VERSION ""

NS_ :

BS_:

BU_: VCU GW PTC EVCOM MCU BMS POD ADCU Diag

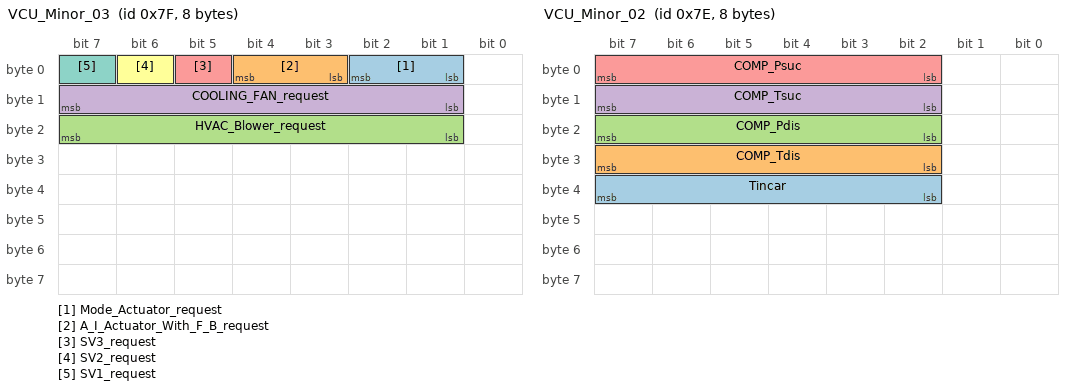
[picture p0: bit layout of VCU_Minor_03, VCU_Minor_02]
BO_ 127 VCU_Minor_03: 8 Vector__XXX
 SG_ Mode_Actuator_request : 2|2@0+ (1,0) [0|2] ""  VCU
 SG_ A_I_Actuator_With_F_B_request : 4|2@0+ (1,0) [0|2] ""  VCU
 SG_ HVAC_Blower_request : 23|7@0+ (1,0) [0|100] "%"  VCU
 SG_ COOLING_FAN_request : 15|7@0+ (1,0) [0|100] "%"  VCU
 SG_ SV3_request : 5|1@0+ (1,0) [0|1] ""  VCU
 SG_ SV2_request : 6|1@0+ (1,0) [0|1] ""  VCU
 SG_ SV1_request : 7|1@0+ (1,0) [0|1] ""  VCU

BO_ 126 VCU_Minor_02: 8 VCU
 SG_ Tincar : 39|6@0+ (0.1,0) [0|5] "V" Vector__XXX
 SG_ COMP_Tdis : 31|6@0+ (0.1,0) [0|5] "V" Vector__XXX
 SG_ COMP_Pdis : 23|6@0+ (0.1,0) [0|5] "V" Vector__XXX
 SG_ COMP_Tsuc : 15|6@0+ (0.1,0) [0|5] "V" Vector__XXX
 SG_ COMP_Psuc : 7|6@0+ (0.1,0) [0|5] "V" Vector__XXX

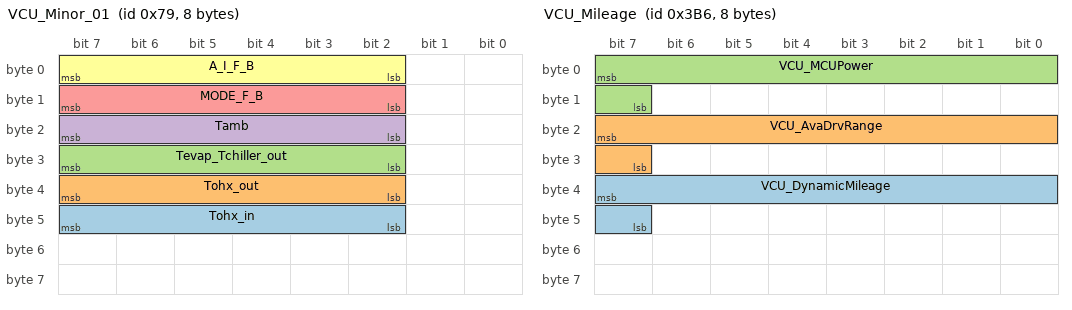
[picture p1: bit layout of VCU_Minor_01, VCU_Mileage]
BO_ 121 VCU_Minor_01: 8 VCU
 SG_ Tohx_in : 47|6@0+ (0.1,0) [0|5] "V" Vector__XXX
 SG_ Tohx_out : 39|6@0+ (0.1,0) [0|5] "V" Vector__XXX
 SG_ Tevap_Tchiller_out : 31|6@0+ (0.1,0) [0|5] "V" Vector__XXX
 SG_ Tamb : 23|6@0+ (0.1,0) [0|5] "V" Vector__XXX
 SG_ MODE_F_B : 15|6@0+ (0.1,0) [0|5] "V" Vector__XXX
 SG_ A_I_F_B : 7|6@0+ (0.1,0) [0|5] "V" Vector__XXX

BO_ 950 VCU_Mileage: 8 Vector__XXX
 SG_ VCU_DynamicMileage : 39|9@0+ (1,0) [0|500] "Km" Vector__XXX
 SG_ VCU_AvaDrvRange : 23|9@0+ (1,0) [0|500] "Km" Vector__XXX
 SG_ VCU_MCUPower : 7|9@0+ (1,-200) [-200|200] "kW" Vector__XXX

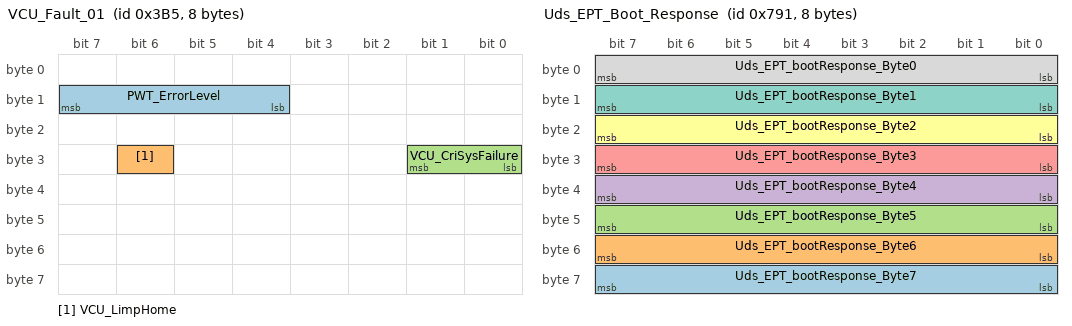
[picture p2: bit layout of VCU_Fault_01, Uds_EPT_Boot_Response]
BO_ 949 VCU_Fault_01: 8 Vector__XXX
 SG_ PWT_ErrorLevel : 15|4@0+ (1,0) [0|15] "" Vector__XXX
 SG_ VCU_LimpHome : 30|1@0+ (1,0) [0|1] "" Vector__XXX
 SG_ VCU_CriSysFailure : 25|2@0+ (1,0) [0|3] "" Vector__XXX

BO_ 1937 Uds_EPT_Boot_Response: 8 Vector__XXX
 SG_ Uds_EPT_bootResponse_Byte7 : 56|8@1+ (1,0) [0|0] ""  Diag
 SG_ Uds_EPT_bootResponse_Byte6 : 48|8@1+ (1,0) [0|0] ""  Diag
 SG_ Uds_EPT_bootResponse_Byte5 : 40|8@1+ (1,0) [0|0] ""  Diag
 SG_ Uds_EPT_bootResponse_Byte4 : 32|8@1+ (1,0) [0|0] ""  Diag
 SG_ Uds_EPT_bootResponse_Byte3 : 24|8@1+ (1,0) [0|0] ""  Diag
 SG_ Uds_EPT_bootResponse_Byte2 : 16|8@1+ (1,0) [0|0] ""  Diag
 SG_ Uds_EPT_bootResponse_Byte1 : 8|8@1+ (1,0) [0|0] ""  Diag
 SG_ Uds_EPT_bootResponse_Byte0 : 0|8@1+ (1,0) [0|0] ""  Diag

BO_ 1809 Uds_EPT_Boot_Request: 8 Diag
 SG_ UDS_EPT_BootCmd3 : 16|8@1+ (1,0) [0|0] "" Vector__XXX
 SG_ UDS_EPT_BootCmd2 : 8|8@1+ (1,0) [0|0] "" Vector__XXX
 SG_ UDS_EPT_BootCmd1 : 0|8@1+ (1,0) [0|0] "" Vector__XXX

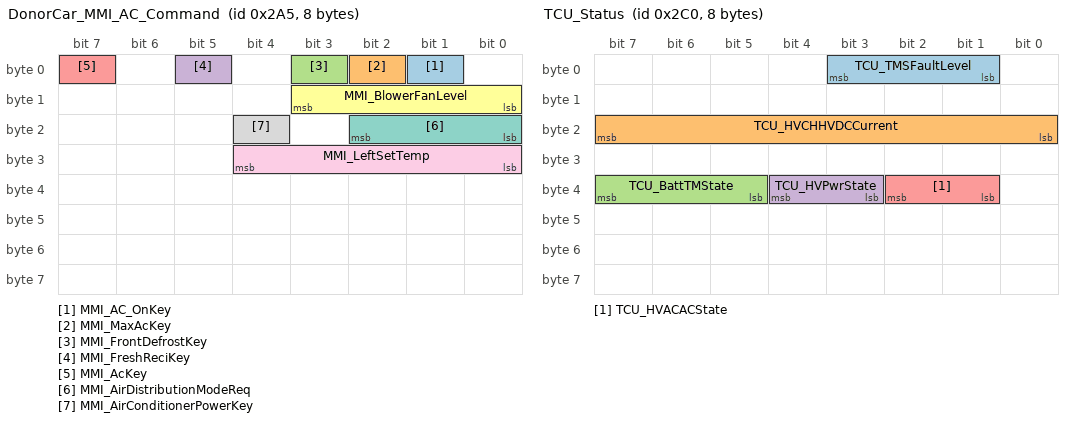
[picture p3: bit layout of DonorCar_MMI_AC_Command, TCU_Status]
BO_ 677 DonorCar_MMI_AC_Command: 8 GW
 SG_ MMI_AC_OnKey : 1|1@0+ (1,0) [0|1] "" Vector__XXX
 SG_ MMI_MaxAcKey : 2|1@0+ (1,0) [0|1] "" Vector__XXX
 SG_ MMI_FrontDefrostKey : 3|1@0+ (1,0) [0|1] "" Vector__XXX
 SG_ MMI_FreshReciKey : 5|1@0+ (1,0) [0|1] "" Vector__XXX
 SG_ MMI_AcKey : 7|1@0+ (1,0) [0|1] "" Vector__XXX
 SG_ MMI_BlowerFanLevel : 11|4@0+ (1,0) [0|15] "" Vector__XXX
 SG_ MMI_AirDistributionModeReq : 18|3@0+ (1,0) [0|7] "" Vector__XXX
 SG_ MMI_AirConditionerPowerKey : 20|1@0+ (1,0) [0|1] "" Vector__XXX
 SG_ MMI_LeftSetTemp : 28|5@0+ (0.5,17) [17|31.5] "℃" Vector__XXX

BO_ 704 TCU_Status: 8 Vector__XXX
 SG_ TCU_TMSFaultLevel : 3|3@0+ (1,0) [0|3] ""  BMS,ADCU
 SG_ TCU_HVCHHVDCCurrent : 23|8@0+ (0.25,0) [0|63.5] "A"  ADCU
 SG_ TCU_BattTMState : 39|3@0+ (1,0) [0|7] ""  BMS
 SG_ TCU_HVPwrState : 36|2@0+ (1,0) [0|3] ""  ADCU
 SG_ TCU_HVACACState : 34|2@0+ (1,0) [0|4] ""  GW

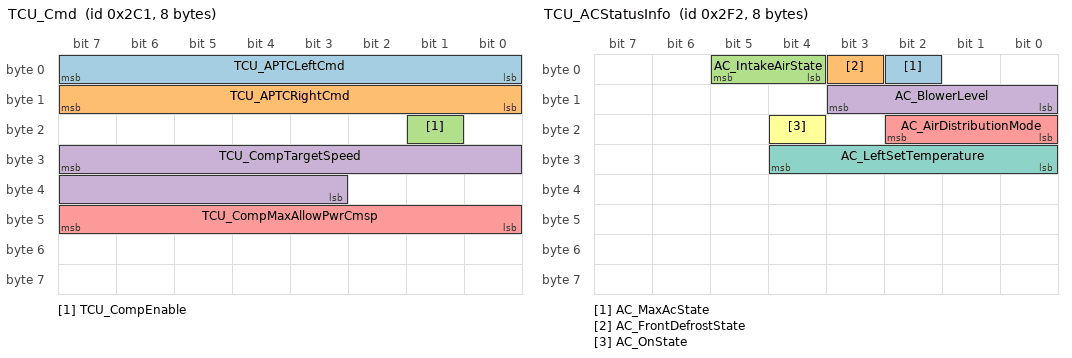
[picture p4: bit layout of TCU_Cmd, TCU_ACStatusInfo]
BO_ 705 TCU_Cmd: 8 Vector__XXX
 SG_ TCU_APTCLeftCmd : 7|8@0+ (1,0) [0|100] "%"  PTC
 SG_ TCU_APTCRightCmd : 15|8@0+ (1,0) [0|100] "%"  PTC
 SG_ TCU_CompEnable : 17|1@0- (1,0) [0|1] ""  EVCOM
 SG_ TCU_CompTargetSpeed : 31|13@0- (1,0) [0|8191] "rpm"  EVCOM
 SG_ TCU_CompMaxAllowPwrCmsp : 47|8@0- (0.04,0) [0|10.16] "KW"  EVCOM

BO_ 706 TCU_AmbientTemp: 8 Vector__XXX
 SG_ TCU_AmbientTemperature : 7|8@0+ (1,-50) [-50|205] ""  GW,ADCU

BO_ 754 TCU_ACStatusInfo: 8 Vector__XXX
 SG_ AC_MaxAcState : 2|1@0+ (1,0) [0|1] ""  GW
 SG_ AC_FrontDefrostState : 3|1@0+ (1,0) [0|1] ""  GW
 SG_ AC_IntakeAirState : 5|2@0+ (1,0) [0|3] ""  GW
 SG_ AC_BlowerLevel : 11|4@0+ (1,0) [0|15] ""  GW
 SG_ AC_AirDistributionMode : 18|3@0+ (1,0) [0|7] ""  GW
 SG_ AC_OnState : 20|1@0+ (1,0) [0|1] ""  GW
 SG_ AC_LeftSetTemperature : 28|5@0+ (0.5,17) [17.5|31.5] "℃"  GW

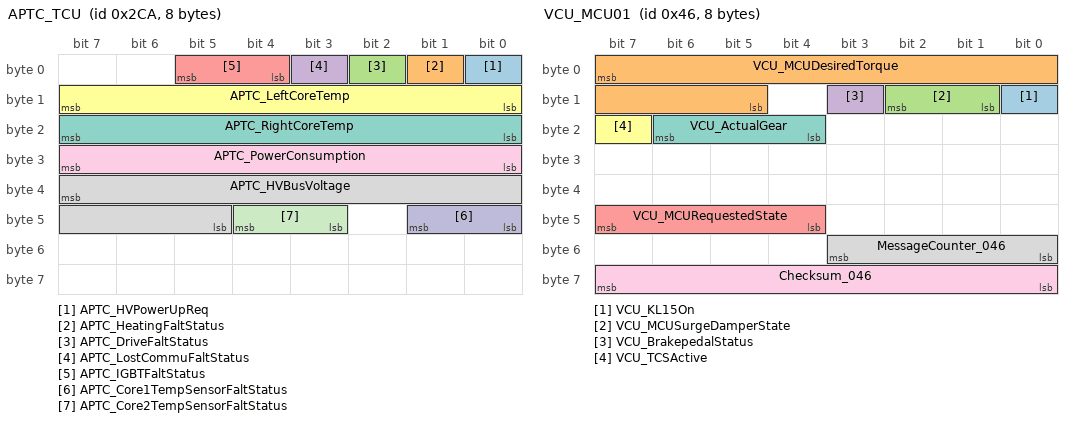
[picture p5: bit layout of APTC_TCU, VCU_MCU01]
BO_ 714 APTC_TCU: 8 PTC
 SG_ APTC_HVPowerUpReq : 0|1@0+ (1,0) [0|1] "" Vector__XXX
 SG_ APTC_HeatingFaltStatus : 1|1@0+ (1,0) [0|1] "" Vector__XXX
 SG_ APTC_DriveFaltStatus : 2|1@0+ (1,0) [0|1] "" Vector__XXX
 SG_ APTC_LostCommuFaltStatus : 3|1@0+ (1,0) [0|1] "" Vector__XXX
 SG_ APTC_IGBTFaltStatus : 5|2@0+ (1,0) [0|3] "" Vector__XXX
 SG_ APTC_LeftCoreTemp : 15|8@0+ (1,-40) [-40|215] "deg" Vector__XXX
 SG_ APTC_RightCoreTemp : 23|8@0+ (1,-40) [-40|215] "deg" Vector__XXX
 SG_ APTC_HVBusVoltage : 39|11@0+ (0.05,0) [0|1020] "V" Vector__XXX
 SG_ APTC_PowerConsumption : 31|8@0+ (0.04,0) [0|10.2] "KW" Vector__XXX
 SG_ APTC_Core1TempSensorFaltStatus : 41|2@0+ (1,0) [0|3] "" Vector__XXX
 SG_ APTC_Core2TempSensorFaltStatus : 44|2@0+ (1,0) [0|3] "" Vector__XXX

BO_ 715 EVCOM_State: 8 EVCOM
 SG_ EVCOM_OverPwrDropFreqError : 0|1@0+ (1,0) [0|1] "" Vector__XXX
 SG_ EVCOM_OverCurDropFreqError : 1|1@0+ (1,0) [0|1] "" Vector__XXX
 SG_ EVCOM_CommunicationError : 2|1@0+ (1,0) [0|1] "" Vector__XXX
 SG_ EVCOM_StandByUnderVolError : 3|1@0+ (1,0) [0|1] "" Vector__XXX
 SG_ EVCOM_StandByOverVolError : 4|1@0+ (1,0) [0|1] "" Vector__XXX
 SG_ EVCOM_UnderVoltageError : 5|1@0+ (1,0) [0|1] "" Vector__XXX
 SG_ EVCOM_OverVoltageError : 6|1@0+ (1,0) [0|1] "" Vector__XXX
 SG_ EVCOM_OverCurrentError : 7|1@0+ (1,0) [0|1] "" Vector__XXX
 SG_ EVCOM_CompDeviceInternTempError : 15|8@0+ (1,-40) [-40|215] "℃" Vector__XXX
 SG_ EVCOM_CompActlSpdValid : 21|1@0+ (1,0) [0|1] "" Vector__XXX
 SG_ EVCOM_CompActlCnsmpCurValid : 22|1@0+ (1,0) [0|1] "" Vector__XXX
 SG_ EVCOM_CompActlPwrCnsmpValid : 23|1@0+ (1,0) [0|1] "" Vector__XXX
 SG_ EVCOM_CompActlSpd : 31|13@0+ (1,0) [0|8191] "rpm" Vector__XXX
 SG_ EVCOM_CompActlPwrCnsmp : 47|8@0+ (0.04,0) [0|10.2] "KW" Vector__XXX
 SG_ EVCOM_CompActlCnsmpCur : 63|8@0+ (0.2,0) [0|51] "A" Vector__XXX
 SG_ EVCOM_ActlOprtMode : 52|2@0+ (1,0) [0|3] "" Vector__XXX
 SG_ EVCOM_FailStatus : 54|1@0+ (1,0) [0|1] "" Vector__XXX
 SG_ EVCOM_CompDeratingOprtStatus : 55|1@0+ (1,0) [0|1] "" Vector__XXX

BO_ 70 VCU_MCU01: 8 Vector__XXX
 SG_ VCU_KL15On : 8|1@0+ (1,0) [0|1] ""  MCU
 SG_ VCU_MCUDesiredTorque : 7|11@0+ (1,-1023) [-1023|1022] "Nm"  MCU
 SG_ VCU_MCUSurgeDamperState : 10|2@0+ (1,0) [0|3] "SED"  MCU
 SG_ VCU_BrakepedalStatus : 11|1@0+ (1,0) [0|1] ""  MCU
 SG_ VCU_MCURequestedState : 47|4@0+ (1,0) [0|15] ""  MCU
 SG_ VCU_TCSActive : 23|1@0+ (1,0) [0|1] ""  MCU
 SG_ VCU_ActualGear : 22|3@0+ (1,0) [0|7] ""  MCU
 SG_ MessageCounter_046 : 51|4@0+ (1,0) [0|15] ""  MCU
 SG_ Checksum_046 : 63|8@0+ (1,0) [0|255] ""  MCU

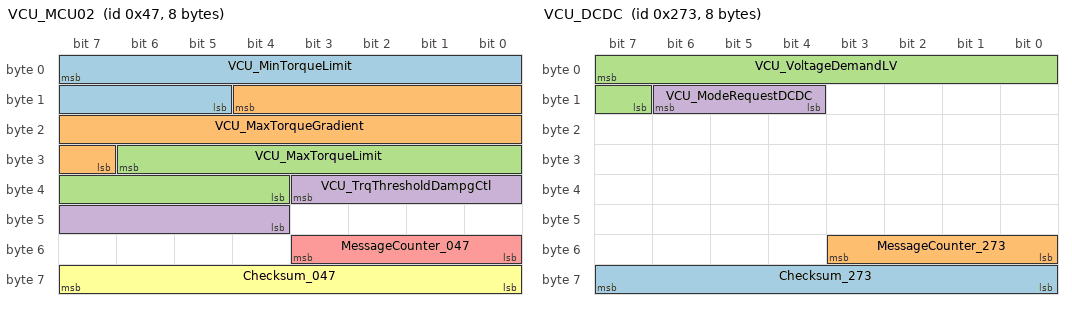
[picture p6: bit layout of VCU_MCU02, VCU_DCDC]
BO_ 71 VCU_MCU02: 8 Vector__XXX
 SG_ VCU_MinTorqueLimit : 7|11@0+ (1,-1023) [-1023|1022] "Nm"  MCU
 SG_ VCU_MaxTorqueGradient : 12|14@0+ (32,0) [0|524192] "Nm/s"  MCU
 SG_ VCU_MaxTorqueLimit : 30|11@0+ (1,-1023) [-1023|1022] "Nm"  MCU
 SG_ VCU_TrqThresholdDampgCtl : 35|8@0+ (0.1,0) [0|25] "Nm"  MCU
 SG_ MessageCounter_047 : 51|4@0+ (1,0) [0|15] ""  MCU
 SG_ Checksum_047 : 63|8@0+ (1,0) [0|255] ""  MCU

BO_ 627 VCU_DCDC: 8 Vector__XXX
 SG_ Checksum_273 : 63|8@0+ (1,0) [0|255] ""  POD
 SG_ MessageCounter_273 : 51|4@0+ (1,0) [0|15] ""  POD
 SG_ VCU_VoltageDemandLV : 7|9@0+ (0.125,0) [0|63.675] "V"  POD,ADCU
 SG_ VCU_ModeRequestDCDC : 14|3@0+ (1,0) [0|7] ""  POD,ADCU

BO_ 629 VCU_POD: 8 Vector__XXX
 SG_ VCU_Enable_DC_Relay : 21|1@0+ (1,0) [0|1] ""  POD

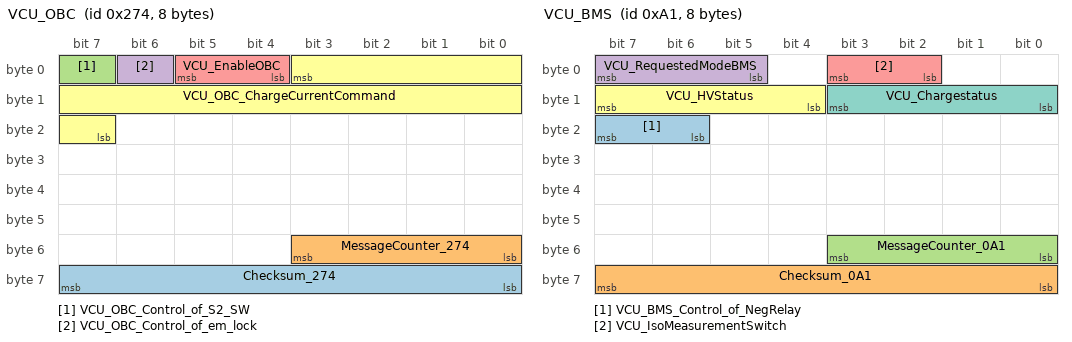
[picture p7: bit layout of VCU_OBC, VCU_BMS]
BO_ 628 VCU_OBC: 8 Vector__XXX
 SG_ Checksum_274 : 63|8@0+ (1,0) [0|255] ""  POD
 SG_ MessageCounter_274 : 51|4@0+ (1,0) [0|15] ""  POD
 SG_ VCU_OBC_Control_of_S2_SW : 7|1@0+ (1,0) [0|1] ""  POD
 SG_ VCU_OBC_Control_of_em_lock : 6|1@0+ (1,0) [0|1] ""  POD
 SG_ VCU_EnableOBC : 5|2@0+ (1,0) [0|3] ""  POD
 SG_ VCU_OBC_ChargeCurrentCommand : 3|13@0+ (0.1,0) [0|500] "A"  POD

BO_ 161 VCU_BMS: 8 Vector__XXX
 SG_ VCU_BMS_Control_of_NegRelay : 23|2@0+ (1,0) [0|3] ""  BMS
 SG_ Checksum_0A1 : 63|8@0+ (1,0) [0|255] ""  BMS
 SG_ MessageCounter_0A1 : 51|4@0+ (1,0) [0|15] ""  BMS
 SG_ VCU_RequestedModeBMS : 7|3@0+ (1,0) [0|7] ""  BMS
 SG_ VCU_IsoMeasurementSwitch : 3|2@0+ (1,0) [0|1] ""  BMS
 SG_ VCU_HVStatus : 15|4@0+ (1,0) [0|15] ""  BMS,ADCU
 SG_ VCU_Chargestatus : 11|4@0+ (1,0) [0|9] ""  BMS,ADCU

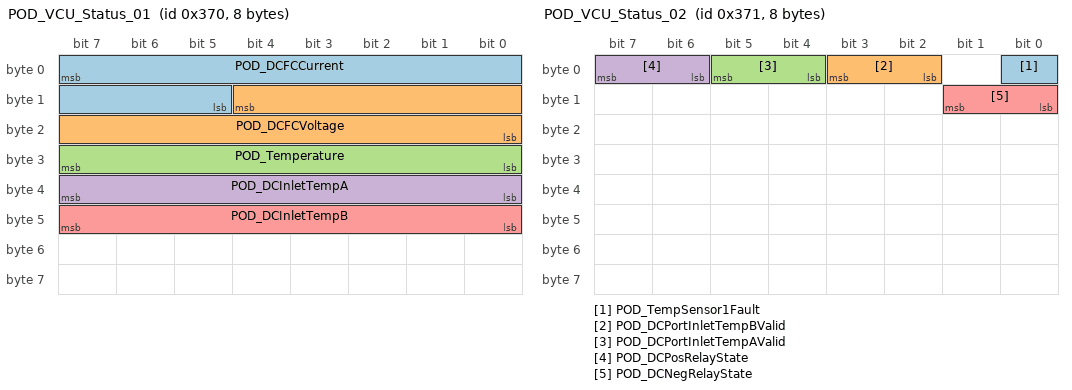
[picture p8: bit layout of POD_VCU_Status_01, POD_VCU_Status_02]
BO_ 880 POD_VCU_Status_01: 8 POD
 SG_ POD_DCFCCurrent : 7|11@0+ (0.5,0) [0|1023.5] "A" Vector__XXX
 SG_ POD_DCFCVoltage : 12|13@0+ (0.1,0) [0|819.1] "V" Vector__XXX
 SG_ POD_Temperature : 31|8@0+ (1,-40) [-40|215] "℃" Vector__XXX
 SG_ POD_DCInletTempA : 39|8@0+ (1,-40) [-40|215] "℃" Vector__XXX
 SG_ POD_DCInletTempB : 47|8@0+ (1,-40) [-40|215] "℃" Vector__XXX

BO_ 881 POD_VCU_Status_02: 8 POD
 SG_ POD_TempSensor1Fault : 0|1@0+ (1,0) [0|1] "" Vector__XXX
 SG_ POD_DCPortInletTempBValid : 3|2@0+ (1,0) [0|2] "" Vector__XXX
 SG_ POD_DCPortInletTempAValid : 5|2@0+ (1,0) [0|2] "" Vector__XXX
 SG_ POD_DCPosRelayState : 7|2@0+ (1,0) [0|2] "" Vector__XXX
 SG_ POD_DCNegRelayState : 9|2@0+ (1,0) [0|2] "" Vector__XXX

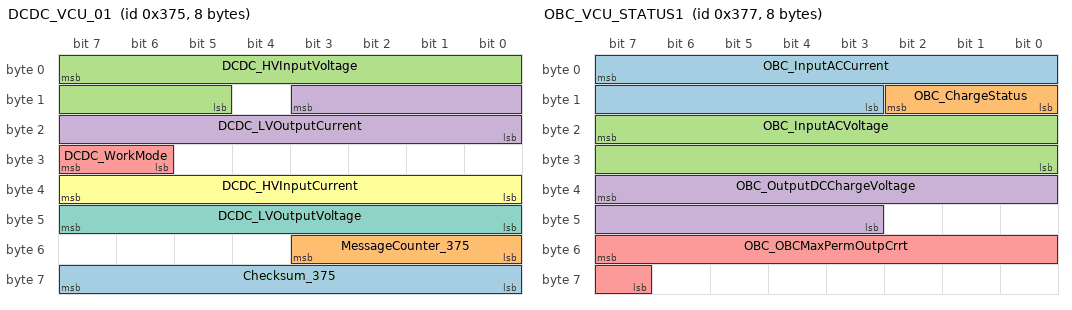
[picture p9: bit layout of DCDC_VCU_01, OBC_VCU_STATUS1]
BO_ 885 DCDC_VCU_01: 8 POD
 SG_ Checksum_375 : 63|8@0+ (1,0) [0|255] "" Vector__XXX
 SG_ MessageCounter_375 : 51|4@0+ (1,0) [0|15] "" Vector__XXX
 SG_ DCDC_HVInputVoltage : 7|11@0+ (0.5,0) [0|1023.5] "V" Vector__XXX
 SG_ DCDC_LVOutputCurrent : 11|12@0+ (0.1,0) [0|400] "A" Vector__XXX
 SG_ DCDC_WorkMode : 31|2@0+ (1,0) [0|3] "" Vector__XXX
 SG_ DCDC_HVInputCurrent : 39|8@0+ (0.1,0) [0|25.5] "A" Vector__XXX
 SG_ DCDC_LVOutputVoltage : 47|8@0+ (0.1,0) [0|25.5] "V" Vector__XXX

BO_ 886 DCDC_VCU_02: 8 POD
 SG_ DCDC_FaultStatus : 7|2@0+ (1,0) [0|3] "" Vector__XXX
 SG_ DCDC_OutputCurrentHighFault : 5|1@0+ (1,0) [0|1] "" Vector__XXX
 SG_ DCDC_InputVoltHighFault : 4|1@0+ (1,0) [0|1] "" Vector__XXX
 SG_ DCDC_InputVoltLowFault : 3|1@0+ (1,0) [0|1] "" Vector__XXX
 SG_ DCDC_OutputVoltHighFault : 2|1@0+ (1,0) [0|1] "" Vector__XXX
 SG_ DCDC_OutputVoltLowFault : 1|1@0+ (1,0) [0|1] "" Vector__XXX
 SG_ DCDC_OutputSOGFault : 0|1@0+ (1,0) [0|1] "" Vector__XXX
 SG_ DCDC_PrimarySideOvertempStatus : 9|1@0+ (1,0) [0|1] "　" Vector__XXX
 SG_ DCDC_SecordarySideOvertempStatus : 15|1@0+ (1,0) [0|1] "　" Vector__XXX
 SG_ DCDC_OBCTempHighFault : 16|1@0+ (1,0) [0|1] "　" Vector__XXX
 SG_ DCDC_OutputCurrentSensorFault : 14|1@0+ (1,0) [0|1] "" Vector__XXX
 SG_ DCDC_OutputTempSensorFault : 13|1@0+ (1,0) [0|1] "" Vector__XXX
 SG_ DCDC_ComFault : 12|1@0+ (1,0) [0|1] "" Vector__XXX
 SG_ DCDC_StopFault : 11|1@0+ (1,0) [0|1] "" Vector__XXX
 SG_ DCDC_InternalFault : 10|1@0+ (1,0) [0|1] "" Vector__XXX
 SG_ DCDC_OBC_CANBusoff : 23|1@0+ (1,0) [0|1] "　" Vector__XXX
 SG_ OBC_DCDC_KL30Error : 22|1@0+ (1,0) [0|1] "　" Vector__XXX
 SG_ DCDC_SecondarySideTemp : 31|8@0+ (1,-40) [-40|215] "℃" Vector__XXX

BO_ 887 OBC_VCU_STATUS1: 8 POD
 SG_ OBC_InputACCurrent : 7|13@0+ (0.1,0) [0|500] "A" Vector__XXX
 SG_ OBC_ChargeStatus : 10|3@0+ (1,0) [0|7] "　" Vector__XXX
 SG_ OBC_InputACVoltage : 23|16@0+ (0.1,0) [0|6553.5] "V" Vector__XXX
 SG_ OBC_OutputDCChargeVoltage : 39|13@0+ (0.1,0) [0|819.1] "V" Vector__XXX
 SG_ OBC_OBCMaxPermOutpCrrt : 55|9@0+ (0.1,0) [0|40] "A" Vector__XXX

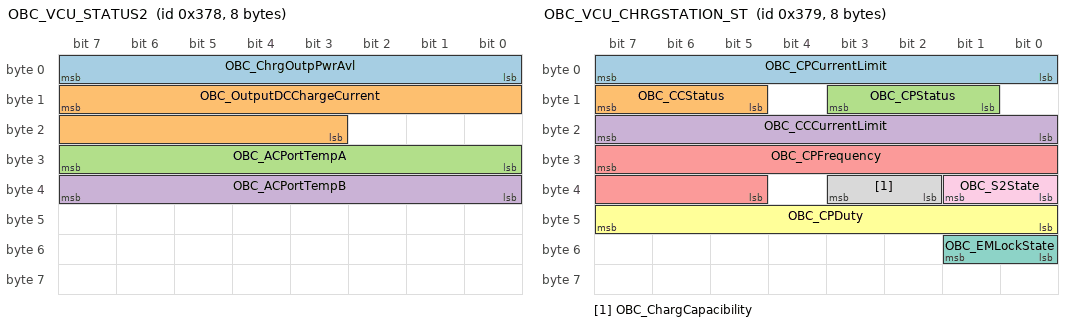
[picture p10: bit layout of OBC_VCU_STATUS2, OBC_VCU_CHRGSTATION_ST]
BO_ 888 OBC_VCU_STATUS2: 8 POD
 SG_ OBC_ChrgOutpPwrAvl : 7|8@0+ (0.1,0) [0|25.5] "KW" Vector__XXX
 SG_ OBC_OutputDCChargeCurrent : 15|13@0+ (0.1,0) [0|500] "A" Vector__XXX
 SG_ OBC_ACPortTempA : 31|8@0+ (1,-40) [-40|215] "℃" Vector__XXX
 SG_ OBC_ACPortTempB : 39|8@0+ (1,-40) [-40|215] "℃" Vector__XXX

BO_ 889 OBC_VCU_CHRGSTATION_ST: 8 POD
 SG_ OBC_CPCurrentLimit : 7|8@0+ (0.4,0) [0|102] "A" Vector__XXX
 SG_ OBC_CCStatus : 15|3@0+ (1,0) [0|7] "　" Vector__XXX
 SG_ OBC_CPStatus : 11|3@0+ (1,0) [0|7] "　" Vector__XXX
 SG_ OBC_CCCurrentLimit : 23|8@0+ (0.4,0) [0|102] "A" Vector__XXX
 SG_ OBC_CPFrequency : 31|11@0+ (1,0) [0|2000] "Hz" Vector__XXX
 SG_ OBC_CPDuty : 47|8@0+ (1,0) [0|255] "%" Vector__XXX
 SG_ OBC_EMLockState : 49|2@0+ (1,0) [0|2] "" Vector__XXX
 SG_ OBC_ChargCapacibility : 35|2@0+ (1,0) [0|2] "" Vector__XXX
 SG_ OBC_S2State : 33|2@0+ (1,0) [0|2] "" Vector__XXX

BO_ 890 OBC_Error_STATUS: 8 POD
 SG_ OBC_ACPortTempASensValid : 7|2@0+ (1,0) [0|2] "" Vector__XXX
 SG_ OBC_ACPortTempBSensValid : 5|2@0+ (1,0) [0|2] "" Vector__XXX
 SG_ OBC_ACPortTempAerror : 9|1@0+ (1,0) [0|1] "　" Vector__XXX
 SG_ OBC_ACPortTempBerror : 24|1@0+ (1,0) [0|1] "　" Vector__XXX
 SG_ OBC_DCVoltLowFault : 3|1@0+ (1,0) [0|1] "" Vector__XXX
 SG_ OBC_FaultLevel : 2|2@0+ (1,0) [0|3] "" Vector__XXX
 SG_ OBC_DCVoltHighFault : 0|1@0+ (1,0) [0|1] "" Vector__XXX
 SG_ OBC_StartUpAllowed : 15|1@0+ (1,0) [0|1] "" Vector__XXX
 SG_ OBC_CommunFault : 14|1@0+ (1,0) [0|1] "" Vector__XXX
 SG_ OBC_DCCurHighFault : 13|1@0+ (1,0) [0|1] "" Vector__XXX
 SG_ OBC_ACVoltHighFault : 11|1@0+ (1,0) [0|1] "" Vector__XXX
 SG_ OBC_ACVoltLowFault : 10|1@0+ (1,0) [0|1] "" Vector__XXX
 SG_ OBC_NlineStatus : 8|1@0+ (1,0) [0|1] "" Vector__XXX
 SG_ OBC_InputFrequencyStatus : 23|1@0+ (1,0) [0|1] "" Vector__XXX
 SG_ OBC_InputPhaseStatus : 22|1@0+ (1,0) [0|1] "" Vector__XXX
 SG_ OBC_InputOverCurrentstatus_R : 21|1@0+ (1,0) [0|1] "" Vector__XXX
 SG_ OBC_InputOverCurrentstatus_S : 20|1@0+ (1,0) [0|1] "" Vector__XXX
 SG_ OBC_InputOverCurrentstatus_T : 19|1@0+ (1,0) [0|1] "" Vector__XXX
 SG_ OBC_PFCUnderVoltageError : 18|1@0+ (1,0) [0|1] "" Vector__XXX
 SG_ OBC_PFCOverVoltageError : 17|1@0+ (1,0) [0|1] "" Vector__XXX
 SG_ OBC_OutputShortError : 16|1@0+ (1,0) [0|1] "" Vector__XXX
 SG_ POD_faultTemp : 30|1@0+ (1,0) [0|1] "" Vector__XXX
 SG_ OBC_PrimarySideOvertempStatus : 29|1@0+ (1,0) [0|1] "" Vector__XXX
 SG_ OBC_SecordarySideOvertempStatus : 28|1@0+ (1,0) [0|1] "" Vector__XXX
 SG_ OBC_ComFault1 : 27|1@0+ (1,0) [0|1] "" Vector__XXX
 SG_ OBC_ComFault2 : 26|1@0+ (1,0) [0|1] "" Vector__XXX
 SG_ OBC_internalFault : 25|1@0+ (1,0) [0|1] "　" Vector__XXX
 SG_ OBC_PrimarySideTemp : 39|8@0+ (1,-40) [-40|210] "℃" Vector__XXX
 SG_ OBC_SecondarySideTemp : 47|8@0+ (1,-40) [-40|210] "℃" Vector__XXX

BO_ 912 BMS_Insulation: 8 BMS
 SG_ BMS_SysRegInsulationValue : 39|16@0+ (1,0) [0|60000] "kΩ" Vector__XXX
 SG_ BMS_InsulationDetectionStatus : 55|1@0+ (1,0) [0|1] "" Vector__XXX

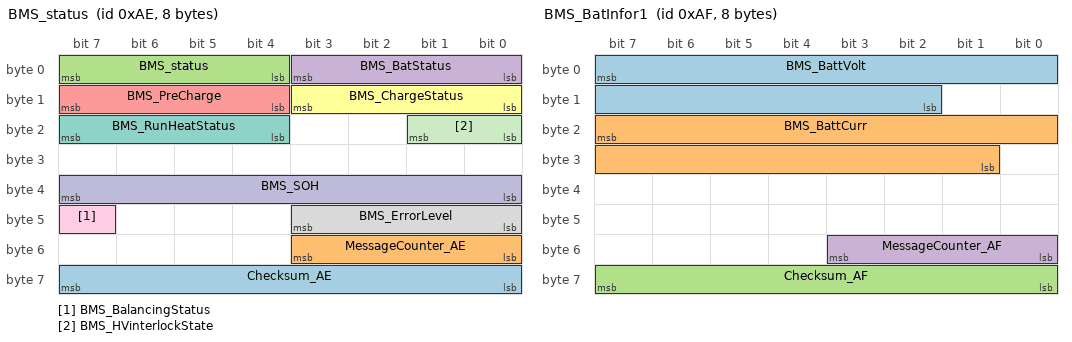
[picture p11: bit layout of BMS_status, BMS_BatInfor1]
BO_ 174 BMS_status: 8 BMS
 SG_ Checksum_AE : 63|8@0+ (1,0) [0|255] "" Vector__XXX
 SG_ MessageCounter_AE : 51|4@0+ (1,0) [0|15] "" Vector__XXX
 SG_ BMS_status : 7|4@0+ (1,0) [0|15] "" Vector__XXX
 SG_ BMS_BatStatus : 3|4@0+ (1,0) [0|4] "" Vector__XXX
 SG_ BMS_PreCharge : 15|4@0+ (1,0) [0|15] "" Vector__XXX
 SG_ BMS_ChargeStatus : 11|4@0+ (1,0) [0|15] "" Vector__XXX
 SG_ BMS_RunHeatStatus : 23|4@0+ (1,0) [0|15] "" Vector__XXX
 SG_ BMS_ErrorLevel : 43|4@0+ (1,0) [0|4] "" Vector__XXX
 SG_ BMS_BalancingStatus : 47|1@0+ (1,0) [0|1] "" Vector__XXX
 SG_ BMS_SOH : 39|8@0+ (0.5,0) [0|100] "%" Vector__XXX
 SG_ BMS_HVinterlockState : 17|2@0+ (1,0) [0|3] "" Vector__XXX

BO_ 175 BMS_BatInfor1: 8 BMS
 SG_ BMS_BattVolt : 7|14@0+ (0.1,0) [0|1000] ""  MCU
 SG_ BMS_BattCurr : 23|15@0+ (0.1,-1024) [-1024|1023] ""  MCU
 SG_ Checksum_AF : 63|8@0+ (1,0) [0|255] "" Vector__XXX
 SG_ MessageCounter_AF : 51|4@0+ (1,0) [0|15] "" Vector__XXX

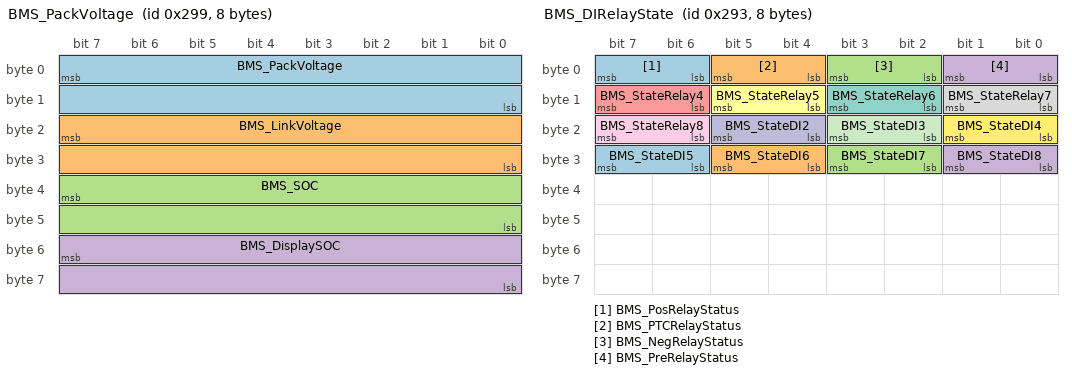
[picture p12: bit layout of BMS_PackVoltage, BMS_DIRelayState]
BO_ 665 BMS_PackVoltage: 8 BMS
 SG_ BMS_PackVoltage : 7|16@0+ (0.1,0) [0|65535] "V" Vector__XXX
 SG_ BMS_LinkVoltage : 23|16@0+ (0.1,0) [0|65535] "V" Vector__XXX
 SG_ BMS_SOC : 39|16@0+ (0.01,-550) [0|100] "%" Vector__XXX
 SG_ BMS_DisplaySOC : 55|16@0+ (0.01,-550) [0|100] "%" Vector__XXX

BO_ 659 BMS_DIRelayState: 8 BMS
 SG_ BMS_PosRelayStatus : 7|2@0+ (1,0) [0|3] "" Vector__XXX
 SG_ BMS_PTCRelayStatus : 5|2@0+ (1,0) [0|3] ""  MCU
 SG_ BMS_NegRelayStatus : 3|2@0+ (1,0) [0|3] "" Vector__XXX
 SG_ BMS_PreRelayStatus : 1|2@0+ (1,0) [0|3] "" Vector__XXX
 SG_ BMS_StateRelay4 : 15|2@0+ (1,0) [0|3] "" Vector__XXX
 SG_ BMS_StateRelay5 : 13|2@0+ (1,0) [0|3] "" Vector__XXX
 SG_ BMS_StateRelay6 : 11|2@0+ (1,0) [0|3] "" Vector__XXX
 SG_ BMS_StateRelay7 : 9|2@0+ (1,0) [0|3] "" Vector__XXX
 SG_ BMS_StateRelay8 : 23|2@0+ (1,0) [0|3] "" Vector__XXX
 SG_ BMS_StateDI2 : 21|2@0+ (1,0) [0|3] "" Vector__XXX
 SG_ BMS_StateDI3 : 19|2@0+ (1,0) [0|3] "" Vector__XXX
 SG_ BMS_StateDI4 : 17|2@0+ (1,0) [0|3] "" Vector__XXX
 SG_ BMS_StateDI5 : 31|2@0+ (1,0) [0|3] "" Vector__XXX
 SG_ BMS_StateDI6 : 29|2@0+ (1,0) [0|3] "" Vector__XXX
 SG_ BMS_StateDI7 : 27|2@0+ (1,0) [0|3] "" Vector__XXX
 SG_ BMS_StateDI8 : 25|2@0+ (1,0) [0|3] "" Vector__XXX

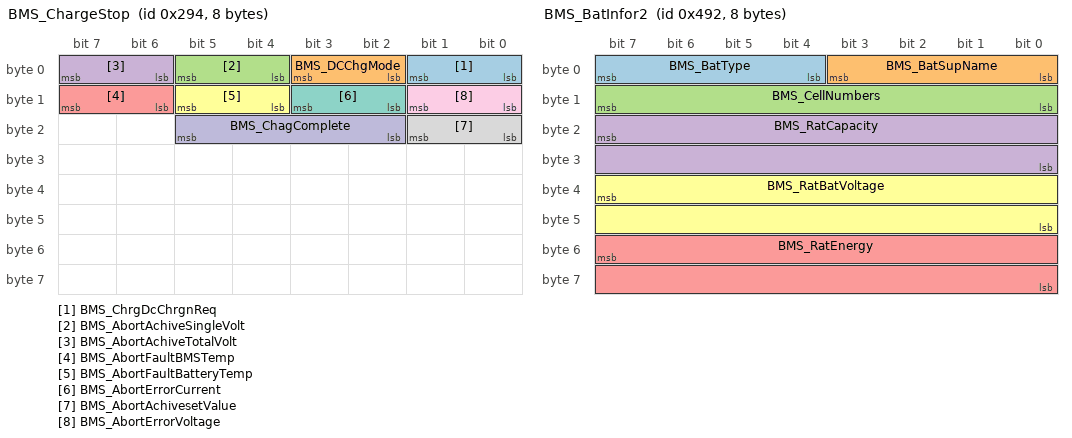
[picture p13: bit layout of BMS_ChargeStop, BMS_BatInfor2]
BO_ 660 BMS_ChargeStop: 8 BMS
 SG_ BMS_ChrgDcChrgnReq : 1|2@0+ (1,0) [0|3] "" Vector__XXX
 SG_ BMS_DCChgMode : 3|2@0+ (1,0) [0|3] "" Vector__XXX
 SG_ BMS_AbortAchiveSingleVolt : 5|2@0+ (1,0) [0|3] "" Vector__XXX
 SG_ BMS_AbortAchiveTotalVolt : 7|2@0+ (1,0) [0|3] "" Vector__XXX
 SG_ BMS_AbortFaultBMSTemp : 15|2@0+ (1,0) [0|3] "" Vector__XXX
 SG_ BMS_AbortFaultBatteryTemp : 13|2@0+ (1,0) [0|3] "" Vector__XXX
 SG_ BMS_AbortErrorCurrent : 11|2@0+ (1,0) [0|3] "" Vector__XXX
 SG_ BMS_AbortAchivesetValue : 17|2@0+ (1,0) [0|3] "" Vector__XXX
 SG_ BMS_AbortErrorVoltage : 9|2@0+ (1,0) [0|3] "" Vector__XXX
 SG_ BMS_ChagComplete : 21|4@0+ (1,0) [0|4] "" Vector__XXX

BO_ 661 BMS_Charge1: 8 BMS
 SG_ BMS_RemChagTime : 7|16@0+ (1,0) [0|3600] "Min" Vector__XXX
 SG_ BMS_MaxChagVoltage : 23|16@0+ (0.1,0) [0|6553.5] "V" Vector__XXX
 SG_ BMS_AllowChagCurrent : 55|16@0+ (0.1,-1000) [-1000|1000] "A" Vector__XXX

BO_ 662 BMS_CurrentLimit: 8 BMS
 SG_ BMS_FeedbackCurr : 7|16@0+ (0.1,-1000) [-1000|1000] "A" Vector__XXX
 SG_ BMS_DisChgCurr : 39|16@0+ (0.1,-1000) [-1000|1000] "A" Vector__XXX

BO_ 1170 BMS_BatInfor2: 8 BMS
 SG_ BMS_BatType : 7|4@0+ (1,0) [0|255] "" Vector__XXX
 SG_ BMS_BatSupName : 3|4@0+ (1,0) [0|4294967295] "" Vector__XXX
 SG_ BMS_CellNumbers : 15|8@0+ (1,0) [0|255] "" Vector__XXX
 SG_ BMS_RatCapacity : 23|16@0+ (0.1,0) [0|6553.5] "Ah" Vector__XXX
 SG_ BMS_RatEnergy : 55|16@0+ (1,0) [0|65535] "KWH" Vector__XXX
 SG_ BMS_RatBatVoltage : 39|16@0+ (0.1,0) [0|6553.5] "V" Vector__XXX

BO_ 1171 BMS_ChargeEnergy: 8 BMS
 SG_ BMS_SingChgkwh : 7|8@0+ (1,0) [0|255] "KWH" Vector__XXX
 SG_ BMS_SumChgkwh : 15|24@0+ (1,0) [0|16777216] "KWH" Vector__XXX
 SG_ BMS_BatChagSum : 39|16@0+ (1,0) [0|3000] "" Vector__XXX

BO_ 1172 BMS_DisChargeEnergy: 8 BMS
 SG_ BMS_RemainCapacity : 31|8@0+ (1,0) [0|250] "Ah" Vector__XXX
 SG_ BMS_SumDisChgkwh : 7|24@0+ (1,0) [0|16777216] "KWH" Vector__XXX

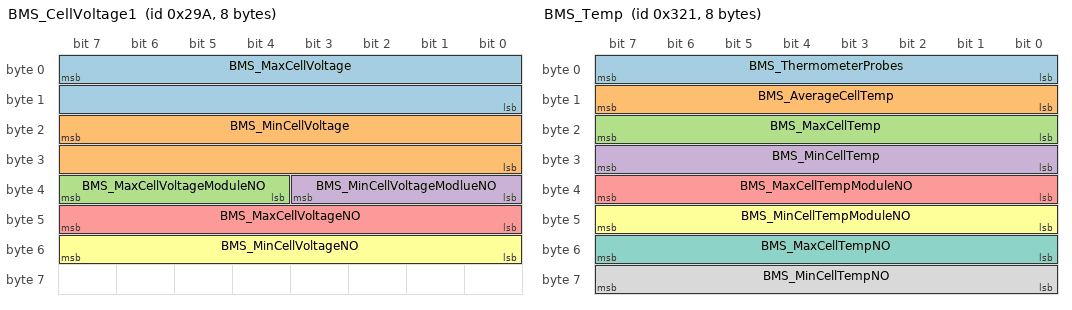
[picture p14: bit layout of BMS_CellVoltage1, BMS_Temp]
BO_ 666 BMS_CellVoltage1: 8 BMS
 SG_ BMS_MaxCellVoltage : 7|16@0+ (0.001,0) [0|65.535] "V" Vector__XXX
 SG_ BMS_MinCellVoltage : 23|16@0+ (0.001,0) [0|65.535] "V" Vector__XXX
 SG_ BMS_MaxCellVoltageModuleNO : 39|4@0+ (1,0) [0|15] "" Vector__XXX
 SG_ BMS_MinCellVoltageModlueNO : 35|4@0+ (1,0) [0|15] "" Vector__XXX
 SG_ BMS_MaxCellVoltageNO : 47|8@0+ (1,0) [0|255] "" Vector__XXX
 SG_ BMS_MinCellVoltageNO : 55|8@0+ (1,0) [0|255] "" Vector__XXX

BO_ 801 BMS_Temp: 8 BMS
 SG_ BMS_ThermometerProbes : 7|8@0+ (1,0) [0|255] "" Vector__XXX
 SG_ BMS_AverageCellTemp : 15|8@0+ (1,-40) [-40|215] "℃" Vector__XXX
 SG_ BMS_MaxCellTemp : 23|8@0+ (1,-40) [-40|215] "℃" Vector__XXX
 SG_ BMS_MinCellTemp : 31|8@0+ (1,-40) [-40|215] "℃" Vector__XXX
 SG_ BMS_MaxCellTempModuleNO : 39|8@0+ (1,0) [0|255] "" Vector__XXX
 SG_ BMS_MinCellTempModuleNO : 47|8@0+ (1,0) [0|255] "" Vector__XXX
 SG_ BMS_MaxCellTempNO : 55|8@0+ (1,0) [0|255] "" Vector__XXX
 SG_ BMS_MinCellTempNO : 63|8@0+ (1,0) [0|255] "" Vector__XXX

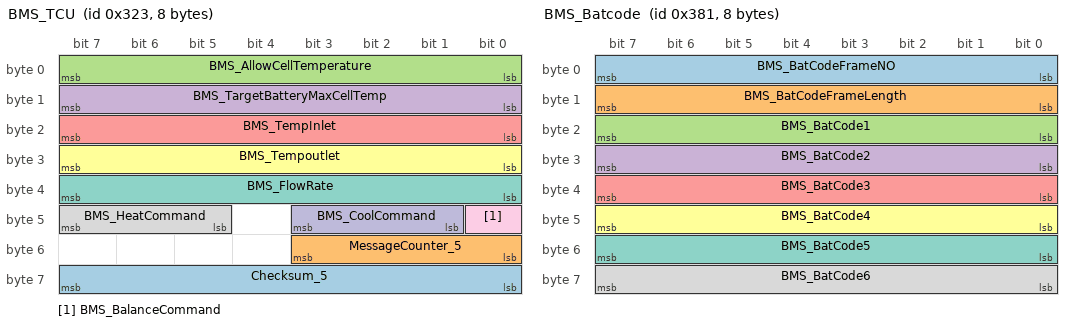
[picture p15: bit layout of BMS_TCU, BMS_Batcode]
BO_ 803 BMS_TCU: 8 BMS
 SG_ Checksum_5 : 63|8@0+ (1,0) [0|255] "" Vector__XXX
 SG_ MessageCounter_5 : 51|4@0+ (1,0) [0|15] "" Vector__XXX
 SG_ BMS_AllowCellTemperature : 7|8@0+ (1,-40) [-40|215] "℃" Vector__XXX
 SG_ BMS_TargetBatteryMaxCellTemp : 15|8@0+ (1,-40) [-40|215] "℃" Vector__XXX
 SG_ BMS_TempInlet : 23|8@0+ (1,-40) [-40|215] "℃" Vector__XXX
 SG_ BMS_Tempoutlet : 31|8@0+ (1,-40) [-40|215] "℃" Vector__XXX
 SG_ BMS_FlowRate : 39|8@0+ (1,0) [0|255] "L/min" Vector__XXX
 SG_ BMS_HeatCommand : 47|3@0+ (1,0) [0|8] "" Vector__XXX
 SG_ BMS_BalanceCommand : 40|1@0+ (1,0) [0|1] "" Vector__XXX
 SG_ BMS_CoolCommand : 43|3@0+ (1,0) [0|8] "" Vector__XXX

BO_ 897 BMS_Batcode: 8 BMS
 SG_ BMS_BatCodeFrameNO : 7|8@0+ (1,0) [0|255] "" Vector__XXX
 SG_ BMS_BatCodeFrameLength : 15|8@0+ (1,0) [0|255] "" Vector__XXX
 SG_ BMS_BatCode1 : 23|8@0+ (1,0) [0|255] "" Vector__XXX
 SG_ BMS_BatCode2 : 31|8@0+ (1,0) [0|255] "" Vector__XXX
 SG_ BMS_BatCode3 : 39|8@0+ (1,0) [0|255] "" Vector__XXX
 SG_ BMS_BatCode4 : 47|8@0+ (1,0) [0|255] "" Vector__XXX
 SG_ BMS_BatCode5 : 55|8@0+ (1,0) [0|255] "" Vector__XXX
 SG_ BMS_BatCode6 : 63|8@0+ (1,0) [0|255] "" Vector__XXX

BO_ 898 BMS_ErrorInfo1: 8 BMS
 SG_ BMS_ErrorCellOverVolt : 7|2@0+ (1,0) [0|3] "" Vector__XXX
 SG_ BMS_ErrorCellUnderVolt : 5|2@0+ (1,0) [0|3] "" Vector__XXX
 SG_ BMS_ErrorCellHighTemp : 3|2@0+ (1,0) [0|3] "" Vector__XXX
 SG_ BMS_ErrorCellLowTemp : 1|2@0+ (1,0) [0|3] "" Vector__XXX
 SG_ BMS_ErrorBattOverVolt : 15|2@0+ (1,0) [0|3] "" Vector__XXX
 SG_ BMS_ErrorBattUnderVolt : 13|2@0+ (1,0) [0|3] "" Vector__XXX
 SG_ BMS_ErrorChaCurrentOver : 11|2@0+ (1,0) [0|3] "" Vector__XXX
 SG_ BMS_ErrorDisChaCurrentOver : 9|2@0+ (1,0) [0|3] "" Vector__XXX
 SG_ BMS_ErrorBSUOffline : 23|1@0+ (1,0) [0|3] "" Vector__XXX
 SG_ BMS_ErrorLeakCurrent : 21|2@0+ (1,0) [0|3] "" Vector__XXX
 SG_ BMS_ErrorCellVoltDiff : 19|2@0+ (1,0) [0|3] "" Vector__XXX
 SG_ BMS_ErrorCellTempDiff : 17|2@0+ (1,0) [0|3] "" Vector__XXX
 SG_ BMS_ErrorBatVolt : 31|2@0+ (1,0) [0|3] "" Vector__XXX
 SG_ BMS_ErrorHallOffline : 29|1@0+ (1,0) [0|3] "" Vector__XXX
 SG_ BMS_ErrorCellVoltOffline : 28|1@0+ (1,0) [0|3] "" Vector__XXX
 SG_ BMS_ErrorCellTempOffline : 27|1@0+ (1,0) [0|3] "" Vector__XXX
 SG_ BMS_ErrorPreChaFailed : 26|1@0+ (1,0) [0|3] "" Vector__XXX
 SG_ BMS_ErrorRelay : 25|1@0+ (1,0) [0|3] "" Vector__XXX
 SG_ BMS_ErrorBSUBalance : 24|1@0+ (1,0) [0|3] "" Vector__XXX
 SG_ BMS_ErrorIsolationSingleLow : 39|2@0+ (1,0) [0|3] "" Vector__XXX
 SG_ BMS_ErrorLowSOC : 37|2@0+ (1,0) [0|3] "" Vector__XXX
 SG_ BMS_ErrorHighSoc : 35|1@0+ (1,0) [0|3] "" Vector__XXX
 SG_ BMS_ErrorSoCJump_RM : 34|1@0+ (1,0) [0|3] "" Vector__XXX
 SG_ BMS_ErrorHVIL : 33|1@0+ (1,0) [0|3] "" Vector__XXX
 SG_ BMS_ErrorEmergencyOffCrash : 32|1@0+ (1,0) [0|3] "" Vector__XXX
 SG_ BMS_ErrorSystemsMatch : 47|1@0+ (1,0) [0|3] "" Vector__XXX
 SG_ BMS_ErrorSmoke : 46|1@0+ (1,0) [0|3] "" Vector__XXX
 SG_ BMS_ErrorLeakDet : 45|1@0+ (1,0) [0|3] "" Vector__XXX
 SG_ BMS_ThermalRunawayFault : 56|1@0+ (1,0) [0|3] "" Vector__XXX
 SG_ BMS_DTC : 55|8@0+ (1,0) [0|255] "" Vector__XXX

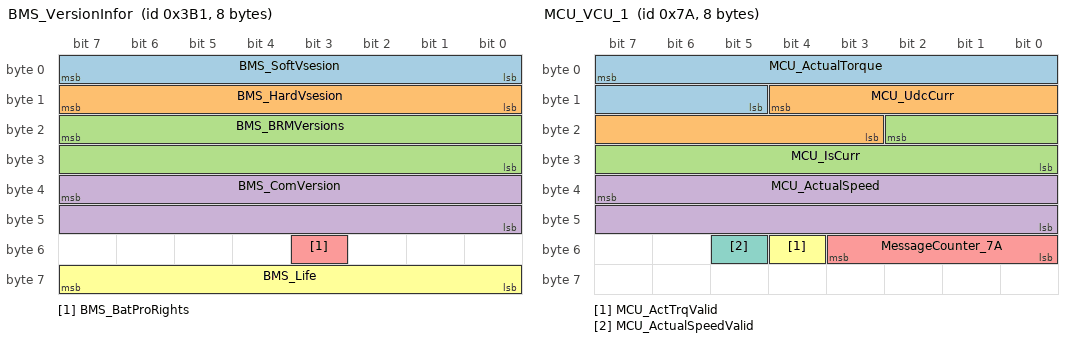
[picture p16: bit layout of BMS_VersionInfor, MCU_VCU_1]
BO_ 945 BMS_VersionInfor: 8 BMS
 SG_ BMS_SoftVsesion : 7|8@0+ (1,0) [0|1] "" Vector__XXX
 SG_ BMS_HardVsesion : 15|8@0+ (1,0) [0|1] "" Vector__XXX
 SG_ BMS_BRMVersions : 23|16@0+ (1,0) [0|65535] "" Vector__XXX
 SG_ BMS_ComVersion : 39|16@0+ (1,0) [0|65535] "" Vector__XXX
 SG_ BMS_BatProRights : 51|1@0+ (1,0) [0|1] "" Vector__XXX
 SG_ BMS_Life : 63|8@0+ (1,0) [0|255] "" Vector__XXX

BO_ 946 BMS_PRO: 8 BMS
 SG_ BMS_BatProDatYear : 7|8@0+ (1,1985) [0|255] "" Vector__XXX
 SG_ BMS_BatProDatMonth : 15|8@0+ (1,0) [0|255] "" Vector__XXX
 SG_ BMS_BatProDatDay : 23|8@0+ (1,0) [0|255] "" Vector__XXX

BO_ 122 MCU_VCU_1: 8 MCU
 SG_ MCU_ActualTorque : 7|11@0+ (1,-1024) [-1024|1023] "" Vector__XXX
 SG_ MCU_UdcCurr : 12|10@0+ (1,0) [0|1021] "" Vector__XXX
 SG_ MCU_IsCurr : 18|11@0+ (0.5,0) [0|1022.5] "" Vector__XXX
 SG_ MCU_ActualSpeed : 39|16@0+ (1,-32768) [-32768|32767] "" Vector__XXX
 SG_ MessageCounter_7A : 51|4@0+ (1,0) [0|15] "" Vector__XXX
 SG_ MCU_ActTrqValid : 52|1@0+ (1,0) [0|1] "" Vector__XXX
 SG_ MCU_ActualSpeedValid : 53|1@0+ (1,0) [0|1] "" Vector__XXX

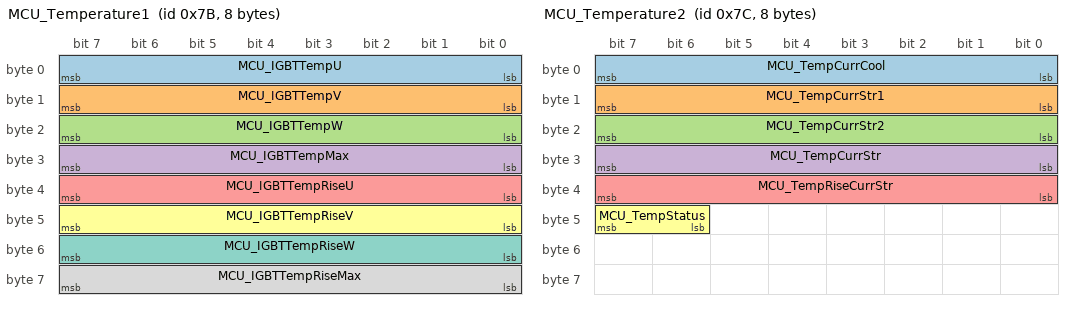
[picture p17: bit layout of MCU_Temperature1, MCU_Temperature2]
BO_ 123 MCU_Temperature1: 8 MCU
 SG_ MCU_IGBTTempU : 7|8@0+ (1,-50) [-50|205] "" Vector__XXX
 SG_ MCU_IGBTTempV : 15|8@0+ (1,-50) [-50|205] "" Vector__XXX
 SG_ MCU_IGBTTempW : 23|8@0+ (1,-50) [-50|205] "" Vector__XXX
 SG_ MCU_IGBTTempMax : 31|8@0+ (1,-50) [-50|205] "" Vector__XXX
 SG_ MCU_IGBTTempRiseU : 39|8@0+ (1,0) [0|255] "" Vector__XXX
 SG_ MCU_IGBTTempRiseV : 47|8@0+ (1,0) [0|255] "" Vector__XXX
 SG_ MCU_IGBTTempRiseW : 55|8@0+ (1,0) [0|255] "" Vector__XXX
 SG_ MCU_IGBTTempRiseMax : 63|8@0+ (1,0) [0|255] "" Vector__XXX

BO_ 124 MCU_Temperature2: 8 MCU
 SG_ MCU_TempCurrCool : 7|8@0+ (1,-50) [-50|205] "" Vector__XXX
 SG_ MCU_TempCurrStr1 : 15|8@0+ (1,-50) [-50|205] "" Vector__XXX
 SG_ MCU_TempCurrStr2 : 23|8@0+ (1,-50) [-50|205] "" Vector__XXX
 SG_ MCU_TempCurrStr : 31|8@0+ (1,-50) [-50|205] "" Vector__XXX
 SG_ MCU_TempRiseCurrStr : 39|8@0+ (1,0) [0|255] "" Vector__XXX
 SG_ MCU_TempStatus : 47|2@0+ (1,0) [0|3] "" Vector__XXX

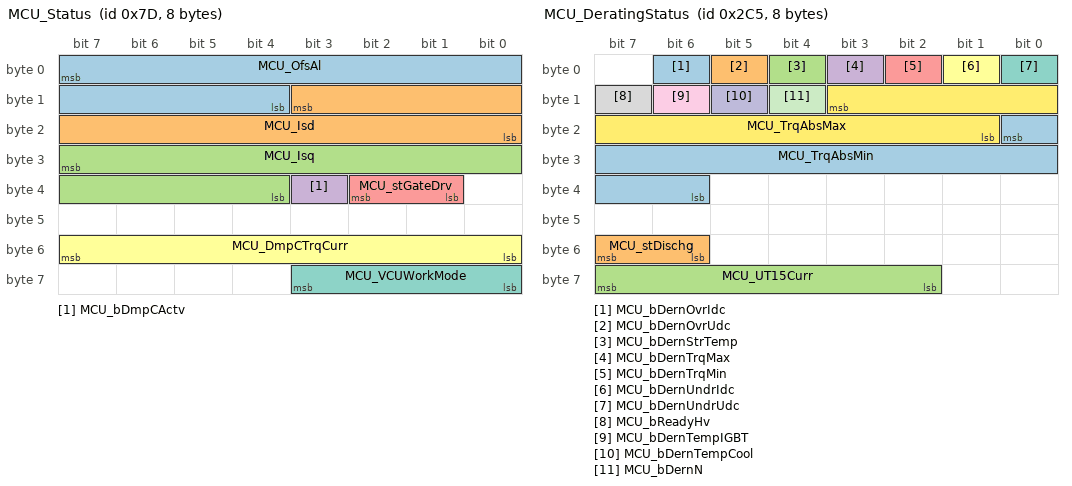
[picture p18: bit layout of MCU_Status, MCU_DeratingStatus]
BO_ 125 MCU_Status: 8 MCU
 SG_ MCU_OfsAl : 7|12@0+ (0.0878906,0) [0|359.736] "" Vector__XXX
 SG_ MCU_Isd : 11|12@0+ (0.5,-1023.5) [-1023.5|1023] "" Vector__XXX
 SG_ MCU_Isq : 31|12@0+ (0.5,-1023.5) [-1023.5|1023] "" Vector__XXX
 SG_ MCU_bDmpCActv : 35|1@0+ (1,0) [0|1] "" Vector__XXX
 SG_ MCU_stGateDrv : 34|2@0+ (1,0) [0|3] "" Vector__XXX
 SG_ MCU_DmpCTrqCurr : 55|8@0+ (0.1,0) [0|25] "Nm" Vector__XXX
 SG_ MCU_VCUWorkMode : 59|4@0+ (1,0) [0|15] "" Vector__XXX

BO_ 709 MCU_DeratingStatus: 8 MCU
 SG_ MCU_bDernOvrIdc : 6|1@0+ (1,0) [0|1] "" Vector__XXX
 SG_ MCU_bDernOvrUdc : 5|1@0+ (1,0) [0|1] "" Vector__XXX
 SG_ MCU_bDernStrTemp : 4|1@0+ (1,0) [0|1] "" Vector__XXX
 SG_ MCU_bDernTrqMax : 3|1@0+ (1,0) [0|1] "" Vector__XXX
 SG_ MCU_bDernTrqMin : 2|1@0+ (1,0) [0|1] "" Vector__XXX
 SG_ MCU_bDernUndrIdc : 1|1@0+ (1,0) [0|1] "" Vector__XXX
 SG_ MCU_bDernUndrUdc : 0|1@0+ (1,0) [0|1] "" Vector__XXX
 SG_ MCU_bReadyHv : 15|1@0+ (1,0) [0|1] "" Vector__XXX
 SG_ MCU_bDernTempIGBT : 14|1@0+ (1,0) [0|1] "" Vector__XXX
 SG_ MCU_bDernTempCool : 13|1@0+ (1,0) [0|1] "" Vector__XXX
 SG_ MCU_bDernN : 12|1@0+ (1,0) [0|1] "" Vector__XXX
 SG_ MCU_TrqAbsMax : 11|11@0+ (1,-1024) [-1024|1023] "" Vector__XXX
 SG_ MCU_TrqAbsMin : 16|11@0+ (1,-1024) [-1024|1023] "" Vector__XXX
 SG_ MCU_stDischg : 55|2@0+ (1,0) [0|3] "" Vector__XXX
 SG_ MCU_UT15Curr : 63|6@0+ (0.5,0) [0|30.5] "" Vector__XXX

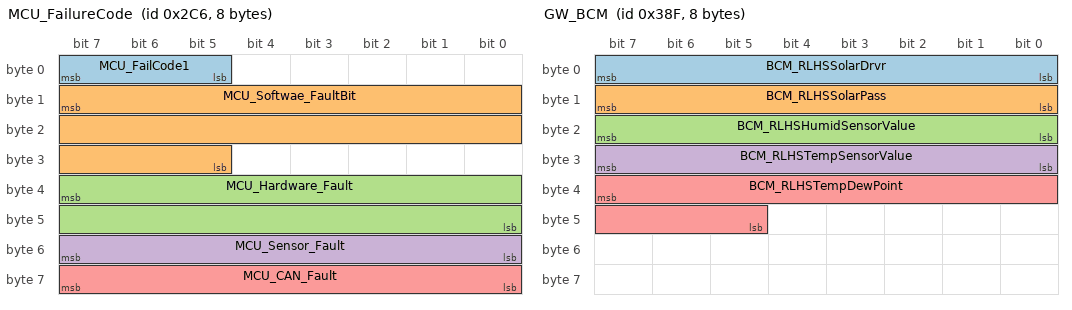
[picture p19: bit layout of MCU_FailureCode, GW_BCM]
BO_ 710 MCU_FailureCode: 8 MCU
 SG_ MCU_FailCode1 : 7|3@0+ (1,0) [0|7] "" Vector__XXX
 SG_ MCU_Softwae_FaultBit : 15|19@0+ (1,0) [0|524287] "" Vector__XXX
 SG_ MCU_Hardware_Fault : 39|16@0+ (1,0) [0|65535] "" Vector__XXX
 SG_ MCU_Sensor_Fault : 55|8@0+ (1,0) [0|255] "" Vector__XXX
 SG_ MCU_CAN_Fault : 63|8@0+ (1,0) [0|255] "" Vector__XXX

BO_ 1178 MCU_SoftwareNumber: 8 MCU
 SG_ MCU_CodeVer : 7|16@0+ (1,0) [0|65535] "" Vector__XXX
 SG_ MCU_DataVer : 23|16@0+ (1,0) [0|65535] "" Vector__XXX
 SG_ MCU_CpldVer : 39|16@0+ (1,0) [0|65535] "" Vector__XXX
 SG_ MCU_HvMcuVer : 55|16@0+ (1,0) [0|65535] "" Vector__XXX

BO_ 1179 MCU_HardwareNumber: 8 MCU
 SG_ MCU_HwVer : 7|16@0+ (1,0) [0|65535] "" Vector__XXX

BO_ 911 GW_BCM: 8 GW
 SG_ BCM_RLHSSolarDrvr : 7|8@0+ (4,0) [0|1000] "W/m2"  ADCU
 SG_ BCM_RLHSSolarPass : 15|8@0+ (4,0) [0|1000] "W/m2"  ADCU
 SG_ BCM_RLHSHumidSensorValue : 23|8@0+ (0.5,0) [0|100] "%"  ADCU
 SG_ BCM_RLHSTempSensorValue : 31|8@0+ (0.5,-40) [-40|120] "℃"  ADCU
 SG_ BCM_RLHSTempDewPoint : 39|11@0+ (0.1,-40) [-40|120] "℃" Vector__XXX

CM_ SG_ 950 VCU_DynamicMileage "Dynamic driving range";
CM_ SG_ 950 VCU_AvaDrvRange "Standard driving range";
CM_ SG_ 950 VCU_MCUPower "Real-time power consumption of motor";
CM_ SG_ 677 MMI_AC_OnKey "ON state key";
CM_ SG_ 677 MMI_MaxAcKey "Max AC key";
CM_ SG_ 677 MMI_FrontDefrostKey "Defrost key";
CM_ SG_ 677 MMI_FreshReciKey "R/F key";
CM_ SG_ 677 MMI_AcKey "AC key";
CM_ SG_ 677 MMI_BlowerFanLevel "Blower fan Level";
CM_ SG_ 677 MMI_AirDistributionModeReq "Air distribution mode request";
CM_ SG_ 677 MMI_AirConditionerPowerKey "Air Conditioner Power Key";
CM_ SG_ 677 MMI_LeftSetTemp "Left set temperature";
CM_ SG_ 704 TCU_TMSFaultLevel "TMS SYSTEM Error level";
CM_ SG_ 704 TCU_HVCHHVDCCurrent "Current Draw of HV-PTC";
CM_ SG_ 704 TCU_BattTMState "TCU battery Thermal management system status
TCU 电池热管理状态";
CM_ SG_ 704 TCU_HVPwrState "TCU High voltage supply Status
TCU系统高压供电状态";
CM_ SG_ 704 TCU_HVACACState "Front HVAC Cool Or Heat Or Vent Auto State
前空调制冷制热通风自动状态";
CM_ SG_ 705 TCU_APTCLeftCmd " Actual power output percent of APTC Left zone 
空气PTC左区输出百分比";
CM_ SG_ 705 TCU_APTCRightCmd " Actual power output percent of APTC Right zone 
空气PTC右区输出百分比";
CM_ SG_ 705 TCU_CompEnable "Compressor Operate Enable Command
压缩机运行使能命令";
CM_ SG_ 705 TCU_CompTargetSpeed "Compressor Target Speed
压缩机目标转速";
CM_ SG_ 705 TCU_CompMaxAllowPwrCmsp "Compressor  Maximum Allowed Power Comsuption
压缩机最大允许消耗功率";
CM_ SG_ 754 AC_MaxAcState "最大制冷状态";
CM_ SG_ 754 AC_FrontDefrostState "除霜状态";
CM_ SG_ 754 AC_IntakeAirState "内外循环进气";
CM_ SG_ 754 AC_BlowerLevel "吹风档位";
CM_ SG_ 754 AC_AirDistributionMode "吹风模式";
CM_ SG_ 754 AC_OnState "空调开启状态";
CM_ SG_ 754 AC_LeftSetTemperature "设定温度";
CM_ SG_ 714 APTC_HVPowerUpReq "APTC high voltage power supply  off line request
APTC 高压下线请求";
CM_ SG_ 714 APTC_HeatingFaltStatus "ptc heater core status";
CM_ SG_ 714 APTC_DriveFaltStatus "ptc driver status";
CM_ SG_ 714 APTC_LostCommuFaltStatus "TCU signal lost";
CM_ SG_ 714 APTC_IGBTFaltStatus "IGBT failure";
CM_ SG_ 714 APTC_LeftCoreTemp "Left core sensor temperature
左侧芯体温度传感器温度
";
CM_ SG_ 714 APTC_RightCoreTemp "Right core sensor temperature
右侧芯体温度传感器温度
";
CM_ SG_ 714 APTC_HVBusVoltage "HV voltage
高压电压值";
CM_ SG_ 714 APTC_PowerConsumption "APTC OutPut Power
APTC 输出功率";
CM_ SG_ 714 APTC_Core1TempSensorFaltStatus "Left core sensor temperature error";
CM_ SG_ 714 APTC_Core2TempSensorFaltStatus "Right core sensor temperature error";
CM_ SG_ 715 EVCOM_OverPwrDropFreqError "EVCOM  Over Power Drop Frequency Error";
CM_ SG_ 715 EVCOM_OverCurDropFreqError "EVCOM  Over Current Drop Frequency Error";
CM_ SG_ 715 EVCOM_CommunicationError "EVCOM  Communication Error";
CM_ SG_ 715 EVCOM_StandByUnderVolError "EVCOM  Stand By Under Voltage Error";
CM_ SG_ 715 EVCOM_StandByOverVolError "EVCOM  Stand By Over Voltage Error";
CM_ SG_ 715 EVCOM_UnderVoltageError "EVCOM  Under Voltage Error";
CM_ SG_ 715 EVCOM_OverVoltageError "EVCOM  Over Voltage Error";
CM_ SG_ 715 EVCOM_OverCurrentError "EVCOM  Over Current Error";
CM_ SG_ 715 EVCOM_CompDeviceInternTempError "Device Internal Temperature
设备内部温度";
CM_ SG_ 715 EVCOM_CompActlSpdValid "Compressor Actual Speed Validity
压缩机实际运转速度有效性";
CM_ SG_ 715 EVCOM_CompActlCnsmpCurValid "Compressor Actual Consuption Current Validity
压缩机运行电流有效性";
CM_ SG_ 715 EVCOM_CompActlPwrCnsmpValid "Compressor Actual Power Consumption Validity
压缩机实际消耗功率有效性";
CM_ SG_ 715 EVCOM_CompActlSpd "Compressor Actual Speed
压缩机实际运转速度";
CM_ SG_ 715 EVCOM_CompActlPwrCnsmp "Compressor Actual Power Consumption 
压缩机实际消耗功率";
CM_ SG_ 715 EVCOM_CompActlCnsmpCur "Compressor Run Current
压缩机运行电流";
CM_ SG_ 715 EVCOM_ActlOprtMode "Air Conditioning Compressor Actual Operation Mode
空调压缩机实际运行模式";
CM_ SG_ 715 EVCOM_FailStatus "Air Conditioning Compressor Failure Status
空调压缩机失效状态";
CM_ SG_ 715 EVCOM_CompDeratingOprtStatus "Air Conditioning Compressor Derating Operation Status
空调压缩机降级运行状态";
CM_ SG_ 70 VCU_KL15On "the bit status of KL15 signal ";
CM_ SG_ 70 VCU_MCUDesiredTorque "Desired torque electric machine";
CM_ SG_ 70 VCU_MCUSurgeDamperState "Requested surge damper state";
CM_ SG_ 70 VCU_BrakepedalStatus "the break pedal status刹车踏板状态";
CM_ SG_ 70 VCU_MCURequestedState "Request to the electric machine";
CM_ SG_ 70 VCU_TCSActive "EN:Tindicates  TCS intervention active，TCS will detect spinning wheels and request torque reduction/limitation
CH:CS激活标志位";
CM_ SG_ 70 VCU_ActualGear "The actual gear status";
CM_ SG_ 70 MessageCounter_046 "the rolling counter of VCU02";
CM_ SG_ 70 Checksum_046 "the checksum of VCU02";
CM_ SG_ 71 VCU_MinTorqueLimit "Lower limit output torque of electric machine";
CM_ SG_ 71 VCU_MaxTorqueGradient "Maximum allowed change rate of actual torque";
CM_ SG_ 71 VCU_MaxTorqueLimit "Upper limit output torque of electric machine";
CM_ SG_ 71 VCU_TrqThresholdDampgCtl "Threshold torque for damping control";
CM_ SG_ 71 MessageCounter_047 "the rolling counter of VCU01";
CM_ SG_ 71 Checksum_047 "the checksum of VCU01";
CM_ SG_ 627 Checksum_273 "CRC-XXX";
CM_ SG_ 627 MessageCounter_273 "Alive Counter_xxx";
CM_ SG_ 627 VCU_VoltageDemandLV "Desired voltage of the DCDC converter LV side (buck mode 13.8v)";
CM_ SG_ 627 VCU_ModeRequestDCDC "Requested state of the DCDC converter";
CM_ SG_ 629 VCU_Enable_DC_Relay "enable: Request for closing DC charging relay";
CM_ SG_ 628 Checksum_274 "Checksum signal for frame";
CM_ SG_ 628 MessageCounter_274 "Message counter signal for frame";
CM_ SG_ 628 VCU_OBC_Control_of_S2_SW "OBC should accept the control signal from VCU to switch the S2 inside the OBC";
CM_ SG_ 628 VCU_OBC_Control_of_em_lock "OBC should accept the control signal from VCU to lock or unlock the actuator in the Inlet for locking or unlocking the charging plug";
CM_ SG_ 628 VCU_EnableOBC "When VCU receiving OBC Charge Status=?Ready? and detecting the status of S2 is closed,VCU send enable;
When  VCU detect that the stop charging condition is met, VUC send disable.";
CM_ SG_ 628 VCU_OBC_ChargeCurrentCommand "OBC output charging current according to this signal.";
CM_ SG_ 161 VCU_BMS_Control_of_NegRelay "Negtive Relay state";
CM_ SG_ 161 Checksum_0A1 "Checksum signal for frame";
CM_ SG_ 161 MessageCounter_0A1 "Message counter signal for frame";
CM_ SG_ 161 VCU_RequestedModeBMS "Interface to request eletric energy storage target mode";
CM_ SG_ 161 VCU_IsoMeasurementSwitch "Isolation measurement switch";
CM_ SG_ 161 VCU_HVStatus "HV System state";
CM_ SG_ 161 VCU_Chargestatus "Charge state";
CM_ SG_ 880 POD_DCFCCurrent "DC relay out side current";
CM_ SG_ 880 POD_DCFCVoltage "DC relay out side voltage";
CM_ SG_ 880 POD_Temperature "This signal reflects the temperature of Coolant outlet and structure";
CM_ SG_ 880 POD_DCInletTempA "Actual DC + temperatur connector";
CM_ SG_ 880 POD_DCInletTempB "Actual DC - temperatur connector";
CM_ SG_ 881 POD_TempSensor1Fault "POD temperature fault of the temporature Coolant outlet or structure";
CM_ SG_ 881 POD_DCPortInletTempBValid "Error state for the temperature sensor. E.g. damaged or short circuit at the temperature sensor in the inlet.";
CM_ SG_ 881 POD_DCPortInletTempAValid "Error state for the temperature sensor. E.g. damaged or short circuit at the temperature sensor in the inlet.";
CM_ SG_ 881 POD_DCPosRelayState "Give feedback of DC charge positive relay state";
CM_ SG_ 881 POD_DCNegRelayState "Give feedback of DC charge negative relay state";
CM_ SG_ 885 Checksum_375 "Checksum signal for frame";
CM_ SG_ 885 MessageCounter_375 "Message counter signal for frame";
CM_ SG_ 885 DCDC_HVInputVoltage "Voltage at high voltage side";
CM_ SG_ 885 DCDC_LVOutputCurrent "Current on low voltage side";
CM_ SG_ 885 DCDC_WorkMode "State DCDC converter";
CM_ SG_ 885 DCDC_HVInputCurrent "Current at high voltage side";
CM_ SG_ 885 DCDC_LVOutputVoltage "Voltage on low voltage side";
CM_ SG_ 886 DCDC_FaultStatus "No fault?this value means the DCDC is normal. Recoverable fault? DCDC will down power and wait for the fault clear, and retry. 
Unrecoverable fault?when DCDC detect this fault, 
DCDC should stop output and power down,when the power is reduced, also need to send this signal.
0x1=Level1--Upload error code(Derating);
0x2=Level2--Upload error code,Recoverable 5 times,if unrecoverable, will upload level 3;
0x3=Level3--stop output(Unrecoverable);";
CM_ SG_ 886 DCDC_OutputCurrentHighFault "DCDC output overcurrent fault";
CM_ SG_ 886 DCDC_InputVoltHighFault "DCDC input overvoltage fault";
CM_ SG_ 886 DCDC_InputVoltLowFault "DCDC input undervoltage fault";
CM_ SG_ 886 DCDC_OutputVoltHighFault "DCDC output overvoltage fault";
CM_ SG_ 886 DCDC_OutputVoltLowFault "DCDC output undervoltage fault";
CM_ SG_ 886 DCDC_OutputSOGFault "DCDC output is short-to-ground fault";
CM_ SG_ 886 DCDC_PrimarySideOvertempStatus "DCDC Primary side overtemperature fault";
CM_ SG_ 886 DCDC_SecordarySideOvertempStatus "DCDC Secordary side overtemperature fault";
CM_ SG_ 886 DCDC_OBCTempHighFault "PCB overtemperature fault（environmental overtemprerature)";
CM_ SG_ 886 DCDC_OutputCurrentSensorFault "DCDC the low-side current sensor is faulty";
CM_ SG_ 886 DCDC_OutputTempSensorFault "DCDC the low-voltage side temperature sensor is faulty";
CM_ SG_ 886 DCDC_ComFault "DCDC communication fault";
CM_ SG_ 886 DCDC_StopFault "DCDC shutdown failure failure";
CM_ SG_ 886 DCDC_InternalFault "DCDC internal error";
CM_ SG_ 886 DCDC_OBC_CANBusoff "CAN  Busoff error";
CM_ SG_ 886 OBC_DCDC_KL30Error "KL30 error";
CM_ SG_ 886 DCDC_SecondarySideTemp "This signal is sent to TMS,according to this signal, TCU control the temporature of water";
CM_ SG_ 887 OBC_InputACCurrent "Report OBC AC current(when singal charging,it is 32A，when three-phase charging ,report the maximum current of one phase)";
CM_ SG_ 887 OBC_ChargeStatus "Idle? when OBC shut up & be able to send message /
Ready?when OBC finish init. & itself detec./Charging/
Fault?when OBC Fault Level=?Recoverable fault?,stop output but not power down
/Level=?Unrecoverable fault?,stop output and pow.down
/Stop?stop pow.down";
CM_ SG_ 887 OBC_InputACVoltage "Input voltage to OBC
This signal means the input phase voltage to OBC. When it is a three-phase charge, the minimum voltage of each phase is reported";
CM_ SG_ 887 OBC_OutputDCChargeVoltage "OutputDCChargeVoltage";
CM_ SG_ 887 OBC_OBCMaxPermOutpCrrt "Report OBC Max Permit Output Current ";
CM_ SG_ 888 OBC_ChrgOutpPwrAvl "Report the maximum output power at present.";
CM_ SG_ 888 OBC_OutputDCChargeCurrent "OBC output current when charge";
CM_ SG_ 888 OBC_ACPortTempA "Actual temperatur connector A";
CM_ SG_ 888 OBC_ACPortTempB "Actual temperatur connector B";
CM_ SG_ 889 OBC_CPCurrentLimit "Maximum AC current of infrastructure signalled by charging station with Duty-Cycle on the CP-PWM-Signal.";
CM_ SG_ 889 OBC_CCStatus "0：unconnected
1：Half-connected
2：1500Ohm
3：680Ohm
4：220Ohm
5:  100Ohm
6:   2000Ohm
7：故障";
CM_ SG_ 889 OBC_CPStatus "Feedback the connected status of CP to VCU";
CM_ SG_ 889 OBC_CCCurrentLimit "Maximum AC current of vehicle plug and cable detected by the EV.
 For different charging plugs and cables e.g. with lower current performance then the charging station there are seperate values of resistors (RC and R4) inside the charging plug";
CM_ SG_ 889 OBC_CPFrequency "CP frequency";
CM_ SG_ 889 OBC_CPDuty "CP Duty";
CM_ SG_ 889 OBC_EMLockState "Give feedback of EM lock status to VCU";
CM_ SG_ 889 OBC_ChargCapacibility "single-phase or three-phase ";
CM_ SG_ 889 OBC_S2State "Give feedback of S2 status to VCU";
CM_ SG_ 890 OBC_ACPortTempASensValid "Error state for the temperature sensor. E.g. damaged or short circuit at the temperature sensor in the inlet.";
CM_ SG_ 890 OBC_ACPortTempBSensValid "Error state for the temperature sensor. E.g. damaged or short circuit at the temperature sensor in the inlet.";
CM_ SG_ 890 OBC_ACPortTempAerror "sensor A temporature error";
CM_ SG_ 890 OBC_ACPortTempBerror "sensor B temporature error";
CM_ SG_ 890 OBC_DCVoltLowFault "Charger DC side undervoltage fault";
CM_ SG_ 890 OBC_FaultLevel "no fault?this value means the OBC is normal. 
Recoverable fault?OBC will down power and wait for the fault clear, and retry. 
Unrecoverable fault?when OBC detect this fault,
 OBC should stop output and power down,when the power is reduced, also need to send this signal";
CM_ SG_ 890 OBC_DCVoltHighFault "Charger DC side overvoltage fault";
CM_ SG_ 890 OBC_StartUpAllowed "OBC startup status";
CM_ SG_ 890 OBC_CommunFault "OBC communication fault";
CM_ SG_ 890 OBC_DCCurHighFault "Charger DC side over current fault";
CM_ SG_ 890 OBC_ACVoltHighFault "Charger AC side overvoltage fault";
CM_ SG_ 890 OBC_ACVoltLowFault "Charger AC side undervoltage fault";
CM_ SG_ 890 OBC_NlineStatus "Whether AC side N line disconnect";
CM_ SG_ 890 OBC_InputFrequencyStatus "Whether AC side frequency abnormal";
CM_ SG_ 890 OBC_InputPhaseStatus "Whether AC side Lack of input phase";
CM_ SG_ 890 OBC_InputOverCurrentstatus_R "PFC input over current between L1 and N";
CM_ SG_ 890 OBC_InputOverCurrentstatus_S "PFC input over current between L2 and N";
CM_ SG_ 890 OBC_InputOverCurrentstatus_T "PFC input over current between L3 and N";
CM_ SG_ 890 OBC_PFCUnderVoltageError "VBUS undervoltage";
CM_ SG_ 890 OBC_PFCOverVoltageError "VBUS over voltage";
CM_ SG_ 890 OBC_OutputShortError "Output short";
CM_ SG_ 890 POD_faultTemp "AC Charge port over temp";
CM_ SG_ 890 OBC_PrimarySideOvertempStatus "Primary side overtemp,at primary side ,we have total three temporature check point, but we only need to check the maximum value error";
CM_ SG_ 890 OBC_SecordarySideOvertempStatus "Secordary side overtemp";
CM_ SG_ 890 OBC_ComFault1 "Microcontroller communication error with primary side";
CM_ SG_ 890 OBC_ComFault2 "Microcontroller communication error with secordary side";
CM_ SG_ 890 OBC_internalFault "OBC internal fault(internal error)";
CM_ SG_ 890 OBC_PrimarySideTemp "This signal is sent to TMS,according to this signal, TCU request reduce the temporature of water,and we have total three temporature check point, but we only need to check the maximum value ";
CM_ SG_ 890 OBC_SecondarySideTemp "This signal is sent to TMS,according to this signal, TCU request reduce the temporature of water.";
CM_ SG_ 912 BMS_SysRegInsulationValue "BMS system insulation value";
CM_ SG_ 912 BMS_InsulationDetectionStatus "BMS insulation detection status";
CM_ SG_ 174 Checksum_AE "Checksum signal for frame";
CM_ SG_ 174 MessageCounter_AE "Message counter signal for frame";
CM_ SG_ 174 BMS_status "State of BMS";
CM_ SG_ 174 BMS_BatStatus "State of battery";
CM_ SG_ 174 BMS_PreCharge "State of BMS Precharge";
CM_ SG_ 174 BMS_ChargeStatus "State of BMS Charge Mode";
CM_ SG_ 174 BMS_RunHeatStatus "State of Heat state when car running";
CM_ SG_ 174 BMS_ErrorLevel "BMS Error Level";
CM_ SG_ 174 BMS_BalancingStatus "Cell balancing status";
CM_ SG_ 174 BMS_SOH "BMS SOH";
CM_ SG_ 174 BMS_HVinterlockState "HV interlock state";
CM_ SG_ 175 BMS_BattVolt "the voltage of dclink from BMS side电池母线电压";
CM_ SG_ 175 BMS_BattCurr "the current of dclink from BMS side电池母线电流";
CM_ SG_ 175 Checksum_AF "Checksum signal for frame";
CM_ SG_ 175 MessageCounter_AF "Message counter signal for frame";
CM_ SG_ 665 BMS_PackVoltage "Pack Inside Volt";
CM_ SG_ 665 BMS_LinkVoltage "Pack Outside Volt";
CM_ SG_ 665 BMS_SOC "BMS Real SOC";
CM_ SG_ 665 BMS_DisplaySOC "BMS Display SOC";
CM_ SG_ 659 BMS_PosRelayStatus "State of  positive relay status";
CM_ SG_ 659 BMS_PTCRelayStatus "the status of PTC relay from BMS side电池PTC继电器状态";
CM_ SG_ 659 BMS_NegRelayStatus "State of  negtive relay status";
CM_ SG_ 659 BMS_PreRelayStatus "State of  precharge relay status";
CM_ SG_ 659 BMS_StateRelay4 "State of  relay 4";
CM_ SG_ 659 BMS_StateRelay5 "State of  relay 5";
CM_ SG_ 659 BMS_StateRelay6 "State of  relay 6";
CM_ SG_ 659 BMS_StateRelay7 "State of  relay 7";
CM_ SG_ 659 BMS_StateRelay8 "State of  relay 8";
CM_ SG_ 659 BMS_StateDI2 "State of DI 2";
CM_ SG_ 659 BMS_StateDI3 "State of DI 3";
CM_ SG_ 659 BMS_StateDI4 "State of DI 4";
CM_ SG_ 659 BMS_StateDI5 "State of DI 5";
CM_ SG_ 659 BMS_StateDI6 "State of DI 6";
CM_ SG_ 659 BMS_StateDI7 "State of DI 7";
CM_ SG_ 659 BMS_StateDI8 "State of DI 8";
CM_ SG_ 661 BMS_RemChagTime "Remaining charging time prediction in minute";
CM_ SG_ 661 BMS_MaxChagVoltage "Maximum allowable charging voltage";
CM_ SG_ 661 BMS_AllowChagCurrent "Maximum allowable charging current";
CM_ SG_ 662 BMS_FeedbackCurr "Maximum feed back charging  current(30S)";
CM_ SG_ 662 BMS_DisChgCurr "Constant discharging  current";
CM_ SG_ 1170 BMS_BatType "Battery type";
CM_ SG_ 1170 BMS_BatSupName "Battery supplier name";
CM_ SG_ 1170 BMS_CellNumbers "Sum of cell in pack";
CM_ SG_ 1170 BMS_RatCapacity "Rated capacity of power battery system";
CM_ SG_ 1170 BMS_RatEnergy "Nominal total energy of power battery";
CM_ SG_ 1170 BMS_RatBatVoltage "Rated Voltage of power battery system";
CM_ SG_ 1171 BMS_SingChgkwh "Single charged electric quantity (charger online)";
CM_ SG_ 1171 BMS_SumChgkwh "Accumulated charged electric quantity ";
CM_ SG_ 1171 BMS_BatChagSum "Sum of how many cycle for battery charged";
CM_ SG_ 1172 BMS_RemainCapacity "Real-time remaining battery capacity";
CM_ SG_ 1172 BMS_SumDisChgkwh "Accumulated discharged electric quantity ";
CM_ SG_ 666 BMS_MaxCellVoltage "The Maximal Cell Voltage";
CM_ SG_ 666 BMS_MinCellVoltage "The Minimal Cell Voltage";
CM_ SG_ 666 BMS_MaxCellVoltageModuleNO "Maximal Cell Voltage module NO";
CM_ SG_ 666 BMS_MinCellVoltageModlueNO "Minimal Cell Voltage module NO";
CM_ SG_ 666 BMS_MaxCellVoltageNO "The Maximal Cell Voltage NO";
CM_ SG_ 666 BMS_MinCellVoltageNO "The Minimal Cell Voltage NO";
CM_ SG_ 801 BMS_ThermometerProbes "Sum of Temperature Probe in PACK";
CM_ SG_ 801 BMS_AverageCellTemp "Average battery cell temperature";
CM_ SG_ 801 BMS_MaxCellTemp "Maximal Cell TemperatureInlet value";
CM_ SG_ 801 BMS_MinCellTemp "Minimal  Cell TemperatureInlet value";
CM_ SG_ 801 BMS_MaxCellTempModuleNO "Maximal Cell TemperatureInlet module NO";
CM_ SG_ 801 BMS_MinCellTempModuleNO "Minimal  Cell TemperatureInlet module NO";
CM_ SG_ 801 BMS_MaxCellTempNO "Maximal Cell TemperatureInlet  NO";
CM_ SG_ 801 BMS_MinCellTempNO "Minimal  Cell TemperatureInlet  NO";
CM_ SG_ 803 Checksum_5 "Checksum signal for frame";
CM_ SG_ 803 MessageCounter_5 "Message counter signal for frame";
CM_ SG_ 803 BMS_AllowCellTemperature "Maximum allowable charging temperature";
CM_ SG_ 803 BMS_TargetBatteryMaxCellTemp "Target battery cell temperature";
CM_ SG_ 803 BMS_TempInlet "Water inlet temperature";
CM_ SG_ 803 BMS_Tempoutlet "Outlet water temperature";
CM_ SG_ 803 BMS_FlowRate "Coolant flow rate";
CM_ SG_ 803 BMS_HeatCommand "Heat command from BMS";
CM_ SG_ 803 BMS_BalanceCommand "Balance command from BMS";
CM_ SG_ 803 BMS_CoolCommand "Cool command from BMS";
CM_ SG_ 897 BMS_BatCodeFrameNO "BatteryCodeNumber ";
CM_ SG_ 897 BMS_BatCodeFrameLength "Length of battery code";
CM_ SG_ 898 BMS_ErrorCellOverVolt "Cell voltage over limit";
CM_ SG_ 898 BMS_ErrorCellUnderVolt "Cell voltage under limit";
CM_ SG_ 898 BMS_ErrorCellHighTemp "Cell temperature over limit";
CM_ SG_ 898 BMS_ErrorCellLowTemp "Cell temperature under limit";
CM_ SG_ 898 BMS_ErrorBattOverVolt "Battery voltage over limit";
CM_ SG_ 898 BMS_ErrorBattUnderVolt "Battery voltage under limit";
CM_ SG_ 898 BMS_ErrorChaCurrentOver "Battery charge current over limit";
CM_ SG_ 898 BMS_ErrorDisChaCurrentOver "Battery discharge current over limit";
CM_ SG_ 898 BMS_ErrorBSUOffline "BSU offline";
CM_ SG_ 898 BMS_ErrorLeakCurrent "Leakage current exceeds the limit";
CM_ SG_ 898 BMS_ErrorCellVoltDiff "Cell‘s voltage diffrence between maximal and minimal one is over limit";
CM_ SG_ 898 BMS_ErrorCellTempDiff "Cell's temperature  diffrence between maximal and minimal one is over limit";
CM_ SG_ 898 BMS_ErrorBatVolt "Battery error";
CM_ SG_ 898 BMS_ErrorHallOffline "Hall offline";
CM_ SG_ 898 BMS_ErrorCellVoltOffline "Cell voltage detector offline";
CM_ SG_ 898 BMS_ErrorCellTempOffline "Cell temperature detector offline";
CM_ SG_ 898 BMS_ErrorPreChaFailed "HV precharg failed";
CM_ SG_ 898 BMS_ErrorRelay "Relay error";
CM_ SG_ 898 BMS_ErrorBSUBalance "BSU balance fuction error";
CM_ SG_ 898 BMS_ErrorIsolationSingleLow "The insulation resistance is too low.";
CM_ SG_ 898 BMS_ErrorLowSOC "SOC under limit";
CM_ SG_ 898 BMS_ErrorHighSoc "SOC over limit";
CM_ SG_ 898 BMS_ErrorSoCJump_RM "SOC jump";
CM_ SG_ 898 BMS_ErrorHVIL "HVIL offline";
CM_ SG_ 898 BMS_ErrorEmergencyOffCrash "Crash signal";
CM_ SG_ 898 BMS_ErrorSystemsMatch "BMS not matched alarm";
CM_ SG_ 898 BMS_ErrorSmoke "Smoke alarm";
CM_ SG_ 898 BMS_ErrorLeakDet "Leakage detection";
CM_ SG_ 898 BMS_DTC "Fault code";
CM_ SG_ 945 BMS_SoftVsesion "BMS software version";
CM_ SG_ 945 BMS_HardVsesion "BMS hardware version";
CM_ SG_ 945 BMS_BRMVersions "BMS versions for BRM";
CM_ SG_ 945 BMS_ComVersion "BMS Communication Protocol Version ";
CM_ SG_ 945 BMS_BatProRights "Battery property rights";
CM_ SG_ 945 BMS_Life "BMS life signal";
CM_ SG_ 946 BMS_BatProDatYear "Battery pack production date year";
CM_ SG_ 946 BMS_BatProDatMonth "Battery pack production date month";
CM_ SG_ 946 BMS_BatProDatDay "Battery pack production date day";
CM_ SG_ 122 MCU_ActualTorque "the actual torque of motor电机实时力矩";
CM_ SG_ 122 MCU_UdcCurr "the actual voltage of udclink实时直流电压";
CM_ SG_ 122 MCU_IsCurr "the actual current 实时直流电流（估算电流）";
CM_ SG_ 122 MCU_ActualSpeed "the actual motor speed电机实时转速";
CM_ SG_ 122 MessageCounter_7A "rolling counter";
CM_ SG_ 122 MCU_ActTrqValid "电机实际扭矩值有效性";
CM_ SG_ 122 MCU_ActualSpeedValid "电机实时转速有效性";
CM_ SG_ 123 MCU_IGBTTempU "the temperature of U phase IGBT/ U项IGBT温度";
CM_ SG_ 123 MCU_IGBTTempV "the temperature of V phase IGBT";
CM_ SG_ 123 MCU_IGBTTempW "the temperature of W phase IGBT";
CM_ SG_ 123 MCU_IGBTTempMax "the temperature of Max phase IGBT";
CM_ SG_ 123 MCU_IGBTTempRiseU "the temperature rise of U phase IGBT/ U项IGBT温升";
CM_ SG_ 123 MCU_IGBTTempRiseV "the temperature rise of V phase IGBT";
CM_ SG_ 123 MCU_IGBTTempRiseW "the temperature  rise of W phase IGBT";
CM_ SG_ 123 MCU_IGBTTempRiseMax "the temperature rise of Max phase IGBT";
CM_ SG_ 124 MCU_TempCurrCool "the temperature of coolant冷却液温度";
CM_ SG_ 124 MCU_TempCurrStr1 "the temperature of stator NTC1 电机温度";
CM_ SG_ 124 MCU_TempCurrStr2 "the temperature of stator NTC2";
CM_ SG_ 124 MCU_TempCurrStr "the temperature of Max stator NTC电机最高温度";
CM_ SG_ 124 MCU_TempRiseCurrStr "the temperature of stator NTC1 电机温升";
CM_ SG_ 124 MCU_TempStatus "The E-motor temperature state温度状态";
CM_ SG_ 125 MCU_OfsAl "the offset angle of motor电机偏移角";
CM_ SG_ 125 MCU_Isd "the actual d axle current of MCU/电机D向电流";
CM_ SG_ 125 MCU_Isq "the actual q axle current of MCU";
CM_ SG_ 125 MCU_bDmpCActv "the damping control enable flag of motor防抖功能状态";
CM_ SG_ 125 MCU_stGateDrv "the gate drive status of MCU开管状态";
CM_ SG_ 125 MCU_DmpCTrqCurr "the actual torque of motor without damping control compensation没有阻尼补偿的电机实时力矩";
CM_ SG_ 125 MCU_VCUWorkMode "the actual running mode of motor工作模式";
CM_ SG_ 709 MCU_bDernOvrIdc "derating from dclink current over直流母线过流限功";
CM_ SG_ 709 MCU_bDernOvrUdc "derating from dclink voltage over直流母线过压限功";
CM_ SG_ 709 MCU_bDernStrTemp "derating from stator temperature over电机过温限功";
CM_ SG_ 709 MCU_bDernTrqMax "derating from troque max limitation超过电机最大外特性限功";
CM_ SG_ 709 MCU_bDernTrqMin "derating from torque min limitation超过电机最小外特性限功";
CM_ SG_ 709 MCU_bDernUndrIdc "derating from dclink current under母线欠流限功";
CM_ SG_ 709 MCU_bDernUndrUdc "derating from dclink voltage under母线欠压限功";
CM_ SG_ 709 MCU_bReadyHv "high voltage ready flag高压预充状态";
CM_ SG_ 709 MCU_bDernTempIGBT "derating from igbt temperature over/ IGBT过温限功";
CM_ SG_ 709 MCU_bDernTempCool "derating from coolant temperature over冷却水过温限功";
CM_ SG_ 709 MCU_bDernN "derating from speed over超速限功";
CM_ SG_ 709 MCU_TrqAbsMax "the maximum allowed torque of E-motor电机最大允许力矩";
CM_ SG_ 709 MCU_TrqAbsMin "the minimum allowed torque of E-motor电机最小允许力矩";
CM_ SG_ 709 MCU_stDischg "the discharge status主动放电状态";
CM_ SG_ 709 MCU_UT15Curr "the actual voltage of Tl15低压电源实时电压";
CM_ SG_ 710 MCU_Softwae_FaultBit "bit0：母线电流过流警告
bit:1：母线电流过流故障
bit2：直流母线过压故障
bit3：直流母线欠压故障
bit4：直流母线过压报警
bit5：直流母线欠压报警
bit6：电机过温警告
bit7：电机过温故障
bit8：逆变器过温警告
bit9：逆变器过温故障
bit10：电机超速警告
bit11：电机超速故障
bit12：MCI通讯掉线故障
bit13：MCU串口校验故障
bit14：reverse
bit15：reverse
bit16：reverse
bit18：reverse
bit19：reverse";
CM_ SG_ 710 MCU_Hardware_Fault "bit0：相电流硬件过流故障
bit:1：CPLD硬件过压故障
bit2：门极驱动电源硬件故障
bit3：CPLD严重故障
bit4：外部低压电压异常
bit5：内部芯片电源故障
bit6：环路互锁故障
bit7：主芯片检查CPLD故障
bit8：高压MCU紧急电源电压故障
bit9：reverse
bit10：reverse
bit11：reverse
bit12：reverse
bit13：reverse
bit14：reverse
bit15：reverse";
CM_ SG_ 710 MCU_Sensor_Fault "bit0：电机温度传感器采样故障
bit:1：相电流传感器故障
bit2：MCU自检故障
bit3：reverse
bit4：reverse
bit5：reverse
bit6：reverse
bit7：reverse";
CM_ SG_ 710 MCU_CAN_Fault "bit0：CAN Bus off
bit:1：reverse
bit2：reverse
bit3：reverse
bit4：reverse
bit5：reverse
bit6：reverse
bit7：reverse";
CM_ SG_ 1178 MCU_CodeVer "the version of TC275 software code软件版本代码";
CM_ SG_ 1178 MCU_DataVer "the version of TC275 software calibration data标定软件版本代码";
CM_ SG_ 1178 MCU_CpldVer "the version of CPLD software软件版本";
CM_ SG_ 1178 MCU_HvMcuVer "the version of Hv Mcu software高压MCU软件版本";
CM_ SG_ 1179 MCU_HwVer "the version of hardware硬件版本";
CM_ SG_ 911 BCM_RLHSSolarDrvr "The left solar sensor measured
左边日照辐射强度  ";
CM_ SG_ 911 BCM_RLHSSolarPass "The right solar sensor measured
右边日照辐射强度  ";
CM_ SG_ 911 BCM_RLHSHumidSensorValue "This signal delivers information about air humid : from 0% to 100%
空气湿度
有效值0x1开始
Start up(初始值) 0x00
Invalid(无效值)0xFF";
CM_ SG_ 911 BCM_RLHSTempSensorValue "This signal delivers information about  temperature in car 
玻璃温度
有效值0x1开始
Start up(初始值) 0x00
Invalid(无效值)0xFF";
CM_ SG_ 911 BCM_RLHSTempDewPoint "露点
有效值0x1开始
Start up(初始值) 0x00
Invalid(无效值)0x7FF";
BA_DEF_ BO_  "GenMsgCycleTime" INT 0 0;
BA_DEF_ BO_  "GenMsgSendType" ENUM  "Cyclic","NotUsed","NotUsed","NotUsed","NotUsed","NotUsed","NotUsed","IfActive","NoMsgSendType","NotUsed";
BA_DEF_ SG_  "GenSigStartValue" INT 0 0;
BA_DEF_ SG_  "GenSigCycleTime" INT 0 0;
BA_DEF_ SG_  "GenSigSendType" ENUM  "Cyclic","OnWrite","OnWriteWithRepetition","OnChange","OnChangeWithRepetition","IfActive","IfActiveWithRepetition","NoSigSendType","NotUsed","NotUsed","NotUsed","NotUsed","NotUsed";
BA_DEF_  "Baudrate" INT 0 1000000;
BA_DEF_  "BusType" STRING ;
BA_DEF_  "NmType" STRING ;
BA_DEF_  "Manufacturer" STRING ;
BA_DEF_ BU_  "NodeLayerModules" STRING ;
BA_DEF_  "NmAsrWaitBusSleepTime" INT 0 65535;
BA_DEF_  "NmAsrTimeoutTime" INT 1 65535;
BA_DEF_  "NmAsrRepeatMessageTime" INT 0 65535;
BA_DEF_ BU_  "NmAsrNodeIdentifier" HEX 0 255;
BA_DEF_  "NmAsrMessageCount" INT 1 256;
BA_DEF_ BU_  "NmAsrCanMsgReducedTime" INT 1 65535;
BA_DEF_  "NmAsrCanMsgCycleTime" INT 1 65535;
BA_DEF_  "NmAsrBaseAddress" HEX 0 2047;
BA_DEF_ BO_  "GenMsgILSupport" ENUM  "no","yes";
BA_DEF_  "DBName" STRING ;
BA_DEF_DEF_  "GenMsgCycleTime" 0;
BA_DEF_DEF_  "GenMsgSendType" "Cyclic";
BA_DEF_DEF_  "GenSigStartValue" 0;
BA_DEF_DEF_  "GenSigCycleTime" 0;
BA_DEF_DEF_  "GenSigSendType" "Cyclic";
BA_DEF_DEF_  "Baudrate" 500000;
BA_DEF_DEF_  "BusType" "";
BA_DEF_DEF_  "NmType" "";
BA_DEF_DEF_  "Manufacturer" "Vector";
BA_DEF_DEF_  "NodeLayerModules" " ";
BA_DEF_DEF_  "NmAsrWaitBusSleepTime" 1500;
BA_DEF_DEF_  "NmAsrTimeoutTime" 2000;
BA_DEF_DEF_  "NmAsrRepeatMessageTime" 3200;
BA_DEF_DEF_  "NmAsrNodeIdentifier" 50;
BA_DEF_DEF_  "NmAsrMessageCount" 128;
BA_DEF_DEF_  "NmAsrCanMsgReducedTime" 320;
BA_DEF_DEF_  "NmAsrCanMsgCycleTime" 640;
BA_DEF_DEF_  "NmAsrBaseAddress" 1280;
BA_DEF_DEF_  "GenMsgILSupport" "no";
BA_DEF_DEF_  "DBName" "";
BA_ "NmType" "NmAsr";
BA_ "BusType" "CAN";
BA_ "NmAsrWaitBusSleepTime" 2000;
BA_ "DBName" "KAMA_FP_EPT_0303";
BA_ "GenMsgILSupport" BO_ 127 1;
BA_ "GenMsgCycleTime" BO_ 127 20;
BA_ "GenMsgCycleTime" BO_ 126 20;
BA_ "GenMsgILSupport" BO_ 126 1;
BA_ "GenMsgCycleTime" BO_ 121 20;
BA_ "GenMsgILSupport" BO_ 121 1;
BA_ "GenMsgCycleTime" BO_ 950 100;
BA_ "GenMsgILSupport" BO_ 950 1;
BA_ "GenMsgCycleTime" BO_ 949 10;
BA_ "GenMsgILSupport" BO_ 949 1;
BA_ "GenMsgILSupport" BO_ 1937 1;
BA_ "GenMsgSendType" BO_ 1937 8;
BA_ "GenMsgCycleTime" BO_ 1809 10;
BA_ "GenMsgILSupport" BO_ 1809 1;
BA_ "GenMsgCycleTime" BO_ 677 100;
BA_ "GenMsgILSupport" BO_ 677 1;
BA_ "GenMsgCycleTime" BO_ 704 100;
BA_ "GenMsgILSupport" BO_ 704 1;
BA_ "GenMsgCycleTime" BO_ 705 100;
BA_ "GenMsgILSupport" BO_ 705 1;
BA_ "GenMsgCycleTime" BO_ 706 100;
BA_ "GenMsgILSupport" BO_ 706 1;
BA_ "GenMsgCycleTime" BO_ 754 100;
BA_ "GenMsgILSupport" BO_ 754 1;
BA_ "GenMsgILSupport" BO_ 714 1;
BA_ "GenMsgCycleTime" BO_ 714 100;
BA_ "GenMsgCycleTime" BO_ 715 100;
BA_ "GenMsgILSupport" BO_ 715 1;
BA_ "GenMsgCycleTime" BO_ 70 10;
BA_ "GenMsgILSupport" BO_ 70 1;
BA_ "GenMsgCycleTime" BO_ 71 20;
BA_ "GenMsgILSupport" BO_ 71 1;
BA_ "GenMsgCycleTime" BO_ 627 100;
BA_ "GenMsgILSupport" BO_ 627 1;
BA_ "GenMsgCycleTime" BO_ 629 50;
BA_ "GenMsgILSupport" BO_ 629 1;
BA_ "GenMsgCycleTime" BO_ 628 100;
BA_ "GenMsgILSupport" BO_ 628 1;
BA_ "GenMsgCycleTime" BO_ 161 20;
BA_ "GenMsgILSupport" BO_ 161 1;
BA_ "GenMsgCycleTime" BO_ 880 100;
BA_ "GenMsgILSupport" BO_ 880 1;
BA_ "GenMsgCycleTime" BO_ 881 100;
BA_ "GenMsgILSupport" BO_ 881 1;
BA_ "GenMsgCycleTime" BO_ 885 100;
BA_ "GenMsgILSupport" BO_ 885 1;
BA_ "GenMsgCycleTime" BO_ 886 200;
BA_ "GenMsgILSupport" BO_ 886 1;
BA_ "GenMsgCycleTime" BO_ 887 100;
BA_ "GenMsgILSupport" BO_ 887 1;
BA_ "GenMsgCycleTime" BO_ 888 100;
BA_ "GenMsgILSupport" BO_ 888 1;
BA_ "GenMsgCycleTime" BO_ 889 50;
BA_ "GenMsgILSupport" BO_ 889 1;
BA_ "GenMsgCycleTime" BO_ 890 200;
BA_ "GenMsgILSupport" BO_ 890 1;
BA_ "GenMsgCycleTime" BO_ 912 1000;
BA_ "GenMsgILSupport" BO_ 912 1;
BA_ "GenMsgCycleTime" BO_ 174 20;
BA_ "GenMsgILSupport" BO_ 174 1;
BA_ "GenMsgILSupport" BO_ 175 1;
BA_ "GenMsgCycleTime" BO_ 175 20;
BA_ "GenMsgCycleTime" BO_ 665 100;
BA_ "GenMsgILSupport" BO_ 665 1;
BA_ "GenMsgILSupport" BO_ 659 1;
BA_ "GenMsgCycleTime" BO_ 659 100;
BA_ "GenMsgILSupport" BO_ 660 1;
BA_ "GenMsgCycleTime" BO_ 660 100;
BA_ "GenMsgILSupport" BO_ 661 1;
BA_ "GenMsgCycleTime" BO_ 661 100;
BA_ "GenMsgILSupport" BO_ 662 1;
BA_ "GenMsgCycleTime" BO_ 662 100;
BA_ "GenMsgILSupport" BO_ 1170 1;
BA_ "GenMsgCycleTime" BO_ 1170 1000;
BA_ "GenMsgILSupport" BO_ 1171 1;
BA_ "GenMsgCycleTime" BO_ 1171 1000;
BA_ "GenMsgCycleTime" BO_ 1172 100;
BA_ "GenMsgILSupport" BO_ 1172 1;
BA_ "GenMsgILSupport" BO_ 666 1;
BA_ "GenMsgCycleTime" BO_ 666 100;
BA_ "GenMsgCycleTime" BO_ 801 100;
BA_ "GenMsgILSupport" BO_ 801 1;
BA_ "GenMsgCycleTime" BO_ 803 200;
BA_ "GenMsgILSupport" BO_ 803 1;
BA_ "GenMsgILSupport" BO_ 897 1;
BA_ "GenMsgCycleTime" BO_ 897 1000;
BA_ "GenMsgCycleTime" BO_ 898 200;
BA_ "GenMsgILSupport" BO_ 898 1;
BA_ "GenMsgCycleTime" BO_ 945 1000;
BA_ "GenMsgILSupport" BO_ 945 1;
BA_ "GenMsgCycleTime" BO_ 946 1000;
BA_ "GenMsgILSupport" BO_ 946 1;
BA_ "GenMsgCycleTime" BO_ 122 10;
BA_ "GenMsgILSupport" BO_ 122 1;
BA_ "GenMsgCycleTime" BO_ 123 500;
BA_ "GenMsgILSupport" BO_ 123 1;
BA_ "GenMsgCycleTime" BO_ 124 500;
BA_ "GenMsgILSupport" BO_ 124 1;
BA_ "GenMsgCycleTime" BO_ 125 20;
BA_ "GenMsgILSupport" BO_ 125 1;
BA_ "GenMsgCycleTime" BO_ 709 100;
BA_ "GenMsgILSupport" BO_ 709 1;
BA_ "GenMsgCycleTime" BO_ 710 100;
BA_ "GenMsgILSupport" BO_ 710 1;
BA_ "GenMsgCycleTime" BO_ 1178 1000;
BA_ "GenMsgILSupport" BO_ 1178 1;
BA_ "GenMsgCycleTime" BO_ 1179 1000;
BA_ "GenMsgILSupport" BO_ 1179 1;
BA_ "GenMsgCycleTime" BO_ 911 100;
BA_ "GenMsgILSupport" BO_ 911 1;
BA_ "GenSigCycleTime" SG_ 127 Mode_Actuator_request 20;
BA_ "GenSigCycleTime" SG_ 127 A_I_Actuator_With_F_B_request 20;
BA_ "GenSigCycleTime" SG_ 127 HVAC_Blower_request 20;
BA_ "GenSigCycleTime" SG_ 127 COOLING_FAN_request 20;
BA_ "GenSigCycleTime" SG_ 127 SV3_request 20;
BA_ "GenSigCycleTime" SG_ 127 SV2_request 20;
BA_ "GenSigCycleTime" SG_ 127 SV1_request 20;
BA_ "GenSigCycleTime" SG_ 126 Tincar 20;
BA_ "GenSigCycleTime" SG_ 126 COMP_Tdis 20;
BA_ "GenSigCycleTime" SG_ 126 COMP_Pdis 20;
BA_ "GenSigCycleTime" SG_ 126 COMP_Tsuc 20;
BA_ "GenSigCycleTime" SG_ 126 COMP_Psuc 20;
BA_ "GenSigCycleTime" SG_ 121 Tohx_in 20;
BA_ "GenSigCycleTime" SG_ 121 Tohx_out 20;
BA_ "GenSigCycleTime" SG_ 121 Tevap_Tchiller_out 20;
BA_ "GenSigCycleTime" SG_ 121 Tamb 20;
BA_ "GenSigCycleTime" SG_ 121 MODE_F_B 20;
BA_ "GenSigCycleTime" SG_ 121 A_I_F_B 20;
BA_ "GenSigStartValue" SG_ 950 VCU_MCUPower 200;
BA_ "GenSigSendType" SG_ 1937 Uds_EPT_bootResponse_Byte7 1;
BA_ "GenSigSendType" SG_ 1937 Uds_EPT_bootResponse_Byte6 1;
BA_ "GenSigSendType" SG_ 1937 Uds_EPT_bootResponse_Byte5 1;
BA_ "GenSigSendType" SG_ 1937 Uds_EPT_bootResponse_Byte4 1;
BA_ "GenSigSendType" SG_ 1937 Uds_EPT_bootResponse_Byte3 1;
BA_ "GenSigSendType" SG_ 1937 Uds_EPT_bootResponse_Byte2 1;
BA_ "GenSigSendType" SG_ 1937 Uds_EPT_bootResponse_Byte1 1;
BA_ "GenSigSendType" SG_ 1937 Uds_EPT_bootResponse_Byte0 1;
BA_ "GenSigStartValue" SG_ 677 MMI_BlowerFanLevel 15;
BA_ "GenSigStartValue" SG_ 677 MMI_AirDistributionModeReq 7;
BA_ "GenSigStartValue" SG_ 706 TCU_AmbientTemperature 255;
BA_ "GenSigStartValue" SG_ 754 AC_LeftSetTemperature 10;
BA_ "GenSigStartValue" SG_ 714 APTC_LeftCoreTemp 40;
BA_ "GenSigStartValue" SG_ 714 APTC_RightCoreTemp 40;
BA_ "GenSigStartValue" SG_ 715 EVCOM_CompDeviceInternTempError 40;
BA_ "GenSigStartValue" SG_ 70 VCU_MCUDesiredTorque 1023;
BA_ "GenSigStartValue" SG_ 71 VCU_MinTorqueLimit 1023;
BA_ "GenSigStartValue" SG_ 71 VCU_MaxTorqueLimit 1023;
BA_ "GenSigStartValue" SG_ 880 POD_Temperature 255;
BA_ "GenSigStartValue" SG_ 880 POD_DCInletTempA 255;
BA_ "GenSigStartValue" SG_ 880 POD_DCInletTempB 255;
BA_ "GenSigStartValue" SG_ 886 DCDC_SecondarySideTemp 255;
BA_ "GenSigStartValue" SG_ 888 OBC_ACPortTempA 255;
BA_ "GenSigStartValue" SG_ 888 OBC_ACPortTempB 255;
BA_ "GenSigStartValue" SG_ 890 OBC_PrimarySideTemp 40;
BA_ "GenSigStartValue" SG_ 890 OBC_SecondarySideTemp 40;
BA_ "GenSigStartValue" SG_ 175 BMS_BattCurr 10240;
BA_ "GenSigStartValue" SG_ 665 BMS_SOC 55000;
BA_ "GenSigStartValue" SG_ 665 BMS_DisplaySOC 55000;
BA_ "GenSigStartValue" SG_ 661 BMS_AllowChagCurrent 10000;
BA_ "GenSigStartValue" SG_ 662 BMS_FeedbackCurr 10000;
BA_ "GenSigStartValue" SG_ 662 BMS_DisChgCurr 10000;
BA_ "GenSigStartValue" SG_ 801 BMS_AverageCellTemp 255;
BA_ "GenSigStartValue" SG_ 801 BMS_MaxCellTemp 255;
BA_ "GenSigStartValue" SG_ 801 BMS_MinCellTemp 255;
BA_ "GenSigStartValue" SG_ 803 BMS_AllowCellTemperature 255;
BA_ "GenSigStartValue" SG_ 803 BMS_TargetBatteryMaxCellTemp 255;
BA_ "GenSigStartValue" SG_ 803 BMS_TempInlet 255;
BA_ "GenSigStartValue" SG_ 803 BMS_Tempoutlet 255;
BA_ "GenSigStartValue" SG_ 803 BMS_FlowRate 255;
BA_ "GenSigStartValue" SG_ 946 BMS_BatProDatYear -1985;
BA_ "GenSigStartValue" SG_ 122 MCU_ActualTorque 1024;
BA_ "GenSigStartValue" SG_ 122 MCU_ActualSpeed 32768;
BA_ "GenSigStartValue" SG_ 123 MCU_IGBTTempU 255;
BA_ "GenSigStartValue" SG_ 123 MCU_IGBTTempV 255;
BA_ "GenSigStartValue" SG_ 123 MCU_IGBTTempW 255;
BA_ "GenSigStartValue" SG_ 123 MCU_IGBTTempMax 255;
BA_ "GenSigStartValue" SG_ 123 MCU_IGBTTempRiseU 255;
BA_ "GenSigStartValue" SG_ 123 MCU_IGBTTempRiseV 255;
BA_ "GenSigStartValue" SG_ 123 MCU_IGBTTempRiseW 255;
BA_ "GenSigStartValue" SG_ 123 MCU_IGBTTempRiseMax 255;
BA_ "GenSigStartValue" SG_ 124 MCU_TempCurrCool 255;
BA_ "GenSigStartValue" SG_ 124 MCU_TempCurrStr1 255;
BA_ "GenSigStartValue" SG_ 124 MCU_TempCurrStr2 255;
BA_ "GenSigStartValue" SG_ 124 MCU_TempCurrStr 255;
BA_ "GenSigStartValue" SG_ 125 MCU_Isd 2047;
BA_ "GenSigStartValue" SG_ 125 MCU_Isq 2047;
BA_ "GenSigStartValue" SG_ 709 MCU_TrqAbsMax 1024;
BA_ "GenSigStartValue" SG_ 709 MCU_TrqAbsMin 1024;
BA_ "GenSigStartValue" SG_ 911 BCM_RLHSTempSensorValue 80;
BA_ "GenSigStartValue" SG_ 911 BCM_RLHSTempDewPoint 400;
VAL_ 127 Mode_Actuator_request 2 "Request_revrsal" 1 "Request_corotation" 0 "Stop" ;
VAL_ 127 A_I_Actuator_With_F_B_request 2 "Request_revrsal" 1 "Request_corotation" 0 "Stop" ;
VAL_ 127 SV3_request 1 "ON" 0 "OFF" ;
VAL_ 127 SV2_request 1 "ON" 0 "OFF" ;
VAL_ 127 SV1_request 1 "ON" 0 "OFF" ;
VAL_ 949 PWT_ErrorLevel 15 "Fault Level15" 14 "Fault Level14" 13 "Fault Level13" 12 "Fault Level12" 11 "Fault Level11" 10 "Fault Level10" 9 "Fault Level9" 8 "Fault Level8" 7 "Fault Level7" 6 "Fault Level6" 5 "Fault Level5" 4 "Fault Level4" 3 "Fault Level3" 2 "Fault Level2" 1 "Fault Level1" 0 "Fault Level0" ;
VAL_ 949 VCU_LimpHome 1 "True" 0 "False" ;
VAL_ 949 VCU_CriSysFailure 3 "Leve3 (emergency power off)" 2 "Leve2 (power loss)" 1 "Leve1 (lighting prompt only)" 0 "No_Warning" ;
VAL_ 677 MMI_AC_OnKey 1 " Pressed" 0 " Not Pressed" ;
VAL_ 677 MMI_MaxAcKey 1 " Pressed" 0 " Not Pressed" ;
VAL_ 677 MMI_FrontDefrostKey 1 " Pressed" 0 " Not Pressed" ;
VAL_ 677 MMI_FreshReciKey 1 " Pressed" 0 " Not Pressed" ;
VAL_ 677 MMI_AcKey 1 " Pressed" 0 " Not Pressed" ;
VAL_ 677 MMI_BlowerFanLevel 15 " Not set" 8 "Blower Level8" 7 "Blower Level7" 6 "Blower Level6" 5 "Blower Level5" 4 "Blower Level4" 3 "Blower Level3" 2 "Blower Level2" 1 "Blower Level1" 0 "Off(Reserved" ;
VAL_ 677 MMI_AirDistributionModeReq 7 "Not set" 6 " Reserved" 5 "Reserved" 4 "Screen" 3 " Foot Screen" 2 "Foot" 1 " Bilevel(Foot face)" 0 "Face" ;
VAL_ 677 MMI_AirConditionerPowerKey 1 " Pressed" 0 " Not Pressed" ;
VAL_ 677 MMI_LeftSetTemp 48 "Hi" 2 "18" 1 "17.5" 0 "Lo" ;
VAL_ 704 TCU_TMSFaultLevel 7 "Reserved" 6 "Reserved" 5 "Reserved" 4 "Fault Level 4" 3 "Fault Level 3" 2 "Fault Level 2" 1 "Fault Level 1" 0 "No Fault" ;
VAL_ 704 TCU_BattTMState 7 "Reserved" 6 "Reserved" 5 "Reserved" 4 "exception mode" 3 "pump only mode" 2 "heating mode" 1 "cooling mode" 0 "sleep mode and no coolant flow" ;
VAL_ 704 TCU_HVPwrState 3 "Reserved" 2 "One Side No Power or Error" 1 "ready to Power On" 0 "ready to Power Off" ;
VAL_ 704 TCU_HVACACState 3 "Reserved" 2 "Manual" 1 "Auto" 0 "Default" ;
VAL_ 705 TCU_CompEnable 1 " Enabled" 0 " Disabled" ;
VAL_ 754 AC_MaxAcState 1 " MAX AC" 0 " OFF" ;
VAL_ 754 AC_FrontDefrostState 1 " ON" 0 " OFF" ;
VAL_ 754 AC_IntakeAirState 3 " Invalid" 2 " Reserved" 1 " Recirculation" 0 " Fresh" ;
VAL_ 754 AC_BlowerLevel 15 " Invalid" 8 "Blower Level =8" 7 "Blower Level =7" 6 "Blower Level =6" 5 "Blower Level =5" 4 "Blower Level =4" 3 "Blower Level =3" 2 "Blower Level =2" 1 "Blower Level =1" 0 " OFF" ;
VAL_ 754 AC_AirDistributionMode 7 " Invalid" 4 " Screen" 3 " Foot Screen(Mix)" 2 " Foo" 1 " Bilevel" 0 " Face" ;
VAL_ 754 AC_OnState 1 " O" 0 " OF" ;
VAL_ 754 AC_LeftSetTemperature 31 " Invalid" 30 " HI" 0 " LO" ;
VAL_ 714 APTC_HVPowerUpReq 1 "APTC failure " 0 "APTC OK" ;
VAL_ 714 APTC_HeatingFaltStatus 1 " error " 0 "no error" ;
VAL_ 714 APTC_DriveFaltStatus 1 "error " 0 "no error" ;
VAL_ 714 APTC_LostCommuFaltStatus 1 "TCU signal losted " 0 "no error" ;
VAL_ 714 APTC_IGBTFaltStatus 3 " BOTH SHORT" 2 "IGBT2 SHORT " 1 "IGBT1 SHORT " 0 "no error" ;
VAL_ 714 APTC_Core1TempSensorFaltStatus 2 "sensor short" 1 "L sensor open " 0 "no error" ;
VAL_ 714 APTC_Core2TempSensorFaltStatus 2 "sensor short" 1 "R sensor open " 0 "no error" ;
VAL_ 715 EVCOM_OverPwrDropFreqError 1 " Error" 0 " No Error" ;
VAL_ 715 EVCOM_OverCurDropFreqError 1 " Error" 0 " No Error" ;
VAL_ 715 EVCOM_CommunicationError 1 " Error" 0 " No Error" ;
VAL_ 715 EVCOM_StandByUnderVolError 1 " Error" 0 " No Error" ;
VAL_ 715 EVCOM_StandByOverVolError 1 " Error" 0 " No Error" ;
VAL_ 715 EVCOM_UnderVoltageError 1 " Error" 0 " No Error" ;
VAL_ 715 EVCOM_OverVoltageError 1 " Error" 0 " No Error" ;
VAL_ 715 EVCOM_OverCurrentError 1 " Error" 0 " No Error" ;
VAL_ 715 EVCOM_CompActlSpdValid 1 " Valid" 0 " Invalid" ;
VAL_ 715 EVCOM_CompActlCnsmpCurValid 1 " Valid" 0 " Invalid" ;
VAL_ 715 EVCOM_CompActlPwrCnsmpValid 1 " Valid" 0 " Invalid" ;
VAL_ 715 EVCOM_ActlOprtMode 3 "emrgncy shutdown" 2 " running" 1 " standby" 0 " off" ;
VAL_ 715 EVCOM_FailStatus 1 " Error" 0 " No Error;" ;
VAL_ 715 EVCOM_CompDeratingOprtStatus 1 " Derating on" 0 " Derating off;" ;
VAL_ 70 VCU_KL15On 1 "On" 0 "Off" ;
VAL_ 70 VCU_MCUDesiredTorque 2047 "Error" 2046 "Init;" ;
VAL_ 70 VCU_MCUSurgeDamperState 2 "DstC_int_ext" 1 "DstC_ext" 0 "DstC_off" ;
VAL_ 70 VCU_BrakepedalStatus 1 " Brake pressed" 0 " Brake Not Pressed" ;
VAL_ 70 VCU_MCURequestedState 5 "Speed Control" 4 "Shutdown" 3 "Discharge" 2 "Active Hearting" 1 "TrqCtr" 0 "Ready " ;
VAL_ 70 VCU_TCSActive 1 "Active" 0 "NotActive" ;
VAL_ 70 VCU_ActualGear 4 "D" 3 "R" 2 "N" 1 "P" 0 "reserve" ;
VAL_ 71 VCU_MinTorqueLimit 2047 "Error" 2046 "Init" ;
VAL_ 71 VCU_MaxTorqueGradient 16383 "Error" 16382 "Init;" ;
VAL_ 71 VCU_MaxTorqueLimit 2047 "Error" 2046 "Init;" ;
VAL_ 71 VCU_TrqThresholdDampgCtl 255 "Error" 254 "Init;" ;
VAL_ 627 VCU_VoltageDemandLV 511 "Error" 510 "Init;" ;
VAL_ 627 VCU_ModeRequestDCDC 2 "Disabl" 1 "Buck" 0 "OFF" ;
VAL_ 629 VCU_Enable_DC_Relay 1 "Close Request" 0 "Open Request" ;
VAL_ 628 VCU_OBC_Control_of_S2_SW 1 "Close" 0 "Open;" ;
VAL_ 628 VCU_OBC_Control_of_em_lock 1 "Close" 0 "Open;" ;
VAL_ 628 VCU_EnableOBC 3 "Disable" 2 "Enable" 1 " Ready" 0 " Sleep" ;
VAL_ 161 VCU_BMS_Control_of_NegRelay 2 "Close" 1 "Open" 0 " Invaild" ;
VAL_ 161 VCU_RequestedModeBMS 7 " InitValue" 6 "  Reserved" 5 " EmergencyOff" 4 " Reserved" 3 " Reserved" 2 " Reserved" 1 " HVActive" 0 " InActive" ;
VAL_ 161 VCU_IsoMeasurementSwitch 1 " Off" 0 " On" ;
VAL_ 161 VCU_HVStatus 5 "Preheating" 4 " Drive ready" 3 " HV ready" 2 " HV start-up" 1 " Standby" 0 " Sleep" ;
VAL_ 161 VCU_Chargestatus 11 "DC Preheating" 10 "AC Preheating" 9 " ?Fault" 8 "?Charging Completed" 7 "? V2L Discharging" 6 "? DC Charging" 5 "? AC Charging" 4 "? V2L Plug Detected" 3 "? DC Plug Detected" 2 "? AC Plug Detected" 1 "? Off Plug" 0 "? Initializing" ;
VAL_ 881 POD_TempSensor1Fault 1 "Fault" 0 "No Fault" ;
VAL_ 881 POD_DCPortInletTempBValid 2 "normal" 1 "Short Circuit " 0 "Damage" ;
VAL_ 881 POD_DCPortInletTempAValid 2 "normal" 1 "Short Circuit " 0 "Damage" ;
VAL_ 881 POD_DCPosRelayState 2 "Error" 1 "Closing" 0 "Opening" ;
VAL_ 881 POD_DCNegRelayState 2 "Error" 1 "Closing" 0 "Opening" ;
VAL_ 885 DCDC_WorkMode 3 "Fault" 2 "Buck" 1 "Standby" 0 "Init" ;
VAL_ 886 DCDC_FaultStatus 3 "Fault Level3" 2 "Fault Level2" 1 "Fault Level1" 0 "No Fault" ;
VAL_ 886 DCDC_OutputCurrentHighFault 1 "Fault" 0 "No Fault" ;
VAL_ 886 DCDC_InputVoltHighFault 1 "Fault" 0 "No Fault" ;
VAL_ 886 DCDC_InputVoltLowFault 1 "Fault" 0 "No Fault" ;
VAL_ 886 DCDC_OutputVoltHighFault 1 "Fault" 0 "No Fault;" ;
VAL_ 886 DCDC_OutputVoltLowFault 1 "Fault" 0 "No Fault" ;
VAL_ 886 DCDC_OutputSOGFault 1 "Fault" 0 "No Fault" ;
VAL_ 886 DCDC_PrimarySideOvertempStatus 1 "Fault" 0 "No Fault" ;
VAL_ 886 DCDC_SecordarySideOvertempStatus 1 "Fault" 0 "No Fault" ;
VAL_ 886 DCDC_OBCTempHighFault 1 "Fault" 0 "No Fault" ;
VAL_ 886 DCDC_OutputCurrentSensorFault 1 "Fault" 0 "No Fault;" ;
VAL_ 886 DCDC_OutputTempSensorFault 1 "Fault" 0 "No Fault" ;
VAL_ 886 DCDC_ComFault 1 "Fault" 0 "No Fault;" ;
VAL_ 886 DCDC_StopFault 1 "Fault" 0 "No Fault;" ;
VAL_ 886 DCDC_InternalFault 1 "Fault" 0 "NoFault" ;
VAL_ 886 DCDC_OBC_CANBusoff 1 "Fault" 0 "No Fault" ;
VAL_ 886 OBC_DCDC_KL30Error 1 "Fault" 0 "No Fault" ;
VAL_ 887 OBC_ChargeStatus 7 " Fault" 6 " Sleep" 5 " V2L Mode" 4 " Pre-heating Mode" 3 " Charging Mode" 2 " Ready" 1 " Standby" 0 " Init" ;
VAL_ 889 OBC_CCStatus 7 " Fault" 6 " 2000 Ohm" 5 " 100 Ohm" 4 "220 Ohm" 3 "680 Ohm " 2 "1500 Ohm " 1 "Half-connected" 0 "Unconnected" ;
VAL_ 889 OBC_CPStatus 7 "Reserve" 6 "Reserve" 5 "Fault" 4 "6V PWM" 3 "6V" 2 "9V PWM" 1 "9V" 0 "Unconnected" ;
VAL_ 889 OBC_EMLockState 2 "Error" 1 "Close" 0 "Open" ;
VAL_ 889 OBC_ChargCapacibility 2 "Error" 1 "Three-phase" 0 "single-phase" ;
VAL_ 889 OBC_S2State 2 "Error" 1 "Close" 0 "Open" ;
VAL_ 890 OBC_ACPortTempASensValid 2 "Normal " 1 "Short Circuit " 0 "Damage" ;
VAL_ 890 OBC_ACPortTempBSensValid 2 "Normal " 1 "Short Circuit " 0 "Damage" ;
VAL_ 890 OBC_ACPortTempAerror 1 "Fault" 0 "No Fault" ;
VAL_ 890 OBC_ACPortTempBerror 1 "Fault" 0 "No Fault" ;
VAL_ 890 OBC_DCVoltLowFault 1 "Fault" 0 "No Fault;" ;
VAL_ 890 OBC_FaultLevel 3 "Level3" 2 "Level2" 1 "Level1" 0 "No Fault" ;
VAL_ 890 OBC_DCVoltHighFault 1 "Fault" 0 "No Fault;" ;
VAL_ 890 OBC_StartUpAllowed 1 "Fault" 0 "No Fault;" ;
VAL_ 890 OBC_CommunFault 1 "Fault" 0 "No Fault;" ;
VAL_ 890 OBC_DCCurHighFault 1 "Fault" 0 "No Fault;" ;
VAL_ 890 OBC_ACVoltHighFault 1 "Fault" 0 "No Fault;" ;
VAL_ 890 OBC_ACVoltLowFault 1 "Fault" 0 "No Fault;" ;
VAL_ 890 OBC_NlineStatus 1 "Fault" 0 "No Fault;" ;
VAL_ 890 OBC_InputFrequencyStatus 1 "Fault" 0 "No Fault;" ;
VAL_ 890 OBC_InputPhaseStatus 1 "Fault" 0 "No Fault;" ;
VAL_ 890 OBC_InputOverCurrentstatus_R 1 "Fault" 0 "No Fault;" ;
VAL_ 890 OBC_InputOverCurrentstatus_S 1 "Fault" 0 "No Fault;" ;
VAL_ 890 OBC_InputOverCurrentstatus_T 1 "Fault" 0 "No Fault;" ;
VAL_ 890 OBC_PFCUnderVoltageError 1 "Fault" 0 "No Fault;" ;
VAL_ 890 OBC_PFCOverVoltageError 1 "Fault" 0 "No Fault;" ;
VAL_ 890 OBC_OutputShortError 1 "Fault" 0 "No Fault;" ;
VAL_ 890 POD_faultTemp 1 "Fault" 0 "No Fault;" ;
VAL_ 890 OBC_PrimarySideOvertempStatus 1 "Fault" 0 "No Fault;" ;
VAL_ 890 OBC_SecordarySideOvertempStatus 1 "Fault" 0 "No Fault;" ;
VAL_ 890 OBC_ComFault1 1 "Fault" 0 "No Fault;" ;
VAL_ 890 OBC_ComFault2 1 "Fault" 0 "No Fault;" ;
VAL_ 890 OBC_internalFault 1 "Fault" 0 "No Fault" ;
VAL_ 912 BMS_InsulationDetectionStatus 1 "active" 0 "stop" ;
VAL_ 174 BMS_status 7 "Invalid" 6 "Error" 5 "Discharge" 4 "AC charge" 3 "DC charge" 2 "running" 1 "standby" 0 "initialize" ;
VAL_ 174 BMS_BatStatus 4 "Shutdown" 3 "Error" 2 "Run" 1 "Standby" 0 "power" ;
VAL_ 174 BMS_PreCharge 3 "Precharge failed" 2 "Precharge finished" 1 "Precharging" 0 "Not precharge" ;
VAL_ 174 BMS_ChargeStatus 7 "Charge stop" 6 "Charge hold" 5 "Charge only(AC)" 4 "Charge only(DC)" 3 "Charge and heat(AC)" 2 "Charge and heat(DC)" 1 "Heat only" 0 "Not charging" ;
VAL_ 174 BMS_RunHeatStatus 3 "Running cool" 2 "App heat" 1 "Target heat" 0 "Running heat" ;
VAL_ 174 BMS_ErrorLevel 4 "level4" 3 "level3" 2 "level2" 1 "level1" 0 "Normal" ;
VAL_ 174 BMS_BalancingStatus 1 "active" 0 "stop" ;
VAL_ 174 BMS_HVinterlockState 1 "Fault" 0 "Normal" ;
VAL_ 659 BMS_PosRelayStatus 3 "Signal Invalid" 2 "Closed" 1 "Opened" 0 "Reserved" ;
VAL_ 659 BMS_PTCRelayStatus 3 "Signal Invalid" 2 "Closed" 1 "Opened" 0 "Reserved" ;
VAL_ 659 BMS_NegRelayStatus 3 "Signal Invalid" 2 "Closed" 1 "Opened" 0 "Reserved" ;
VAL_ 659 BMS_PreRelayStatus 3 "Signal Invalid" 2 "Closed" 1 "Opened" 0 "Reserved" ;
VAL_ 660 BMS_ChrgDcChrgnReq 2 " charging request" 1 "no charging request" 0 "invalid" ;
VAL_ 660 BMS_DCChgMode 2 "constant current" 1 "constant voltage" 0 "ready" ;
VAL_ 660 BMS_AbortAchiveSingleVolt 2 "untrustable" 1 "reached" 0 "not reached" ;
VAL_ 660 BMS_AbortAchiveTotalVolt 2 "untrustable" 1 "reached" 0 "not reached" ;
VAL_ 660 BMS_AbortFaultBMSTemp 2 "untrustable" 1 "over temp" 0 "normal" ;
VAL_ 660 BMS_AbortFaultBatteryTemp 2 "untrustable" 1 "over temp" 0 "normal" ;
VAL_ 660 BMS_AbortErrorCurrent 2 "untrustable" 1 "over current" 0 "normal" ;
VAL_ 660 BMS_AbortAchivesetValue 2 "untrustable" 1 "reached" 0 "not reached" ;
VAL_ 660 BMS_AbortErrorVoltage 2 "untrustable" 1 "abnormal" 0 "normal" ;
VAL_ 660 BMS_ChagComplete 3 "During Charging" 2 "Untrustable" 1 " Abnormal completion" 0 " Normal Completion" ;
VAL_ 803 BMS_HeatCommand 7 "Target heat" 6 "Reserved" 5 "Keep warm" 4 "Running heat" 3 "Charge and heat(AC)" 2 "Charge and heat(DC)" 1 "Preheating" 0 "Not heat" ;
VAL_ 803 BMS_BalanceCommand 1 " request " 0 "No request" ;
VAL_ 803 BMS_CoolCommand 7 "Target cool" 6 "Reserved" 5 "Keep cool" 4 "Running cool" 3 "Charge and cool(AC)" 2 "Charge and cool(DC)" 1 "Reserved" 0 "Not cooling" ;
VAL_ 898 BMS_ErrorCellOverVolt 3 "Fault Level3" 2 "Fault Level2" 1 "Fault Level1" 0 "Normal" ;
VAL_ 898 BMS_ErrorCellUnderVolt 3 "Fault Level3" 2 "Fault Level2" 1 "Fault Level1" 0 "Normal" ;
VAL_ 898 BMS_ErrorCellHighTemp 3 "Fault Level3" 2 "Fault Level2" 1 "Fault Level1" 0 "Normal" ;
VAL_ 898 BMS_ErrorCellLowTemp 3 "Fault Level3" 2 "Fault Level2" 1 "Fault Level1" 0 "Normal" ;
VAL_ 898 BMS_ErrorBattOverVolt 3 "Fault Level3" 2 "Fault Level2" 1 "Fault Level1" 0 "Normal" ;
VAL_ 898 BMS_ErrorBattUnderVolt 3 "Fault Level3" 2 "Fault Level2" 1 "Fault Level1" 0 "Normal" ;
VAL_ 898 BMS_ErrorChaCurrentOver 3 "Fault Level3" 2 "Fault Level2" 1 "Fault Level1" 0 "Normal" ;
VAL_ 898 BMS_ErrorDisChaCurrentOver 3 "Fault Level3" 2 "Fault Level2" 1 "Fault Level1" 0 "Normal" ;
VAL_ 898 BMS_ErrorBSUOffline 1 "Fault" 0 "Normal" ;
VAL_ 898 BMS_ErrorLeakCurrent 3 "Fault Level3" 2 "Fault Level2" 1 "Fault Level1" 0 "Normal" ;
VAL_ 898 BMS_ErrorCellVoltDiff 3 "Fault Level3" 2 "Fault Level2" 1 "Fault Level1" 0 "Normal" ;
VAL_ 898 BMS_ErrorCellTempDiff 3 "Fault Level3" 2 "Fault Level2" 1 "Fault Level1" 0 "Normal" ;
VAL_ 898 BMS_ErrorBatVolt 3 "Fault Level3" 2 "Fault Level2" 1 "Fault Level1" 0 "Normal" ;
VAL_ 898 BMS_ErrorHallOffline 1 "Fault" 0 "Normal" ;
VAL_ 898 BMS_ErrorCellVoltOffline 1 "Fault" 0 "Normal;" ;
VAL_ 898 BMS_ErrorCellTempOffline 1 "Fault" 0 "Normal" ;
VAL_ 898 BMS_ErrorPreChaFailed 1 "Fault" 0 "Normal;" ;
VAL_ 898 BMS_ErrorRelay 1 "Fault" 0 "Normal" ;
VAL_ 898 BMS_ErrorBSUBalance 1 "Fault" 0 "Normal;" ;
VAL_ 898 BMS_ErrorIsolationSingleLow 3 "Fault Level3" 2 "Fault Level2" 1 "Fault Level1" 0 "Normal" ;
VAL_ 898 BMS_ErrorLowSOC 3 "Fault Level3" 2 "Fault Level2" 1 "Fault Level1" 0 "Normal" ;
VAL_ 898 BMS_ErrorHighSoc 1 "Fault" 0 "Normal;" ;
VAL_ 898 BMS_ErrorSoCJump_RM 1 "Fault" 0 "Normal" ;
VAL_ 898 BMS_ErrorHVIL 1 "Fault" 0 "Normal;" ;
VAL_ 898 BMS_ErrorEmergencyOffCrash 1 "Fault" 0 "Normal;" ;
VAL_ 898 BMS_ErrorSystemsMatch 1 "Fault" 0 "Normal;" ;
VAL_ 898 BMS_ErrorSmoke 1 "Fault" 0 "Normal;" ;
VAL_ 898 BMS_ErrorLeakDet 1 "Fault" 0 "Normal" ;
VAL_ 898 BMS_ThermalRunawayFault 1 "Fault" 0 "Normal" ;
VAL_ 945 BMS_BatProRights 1 "Buy" 0 "lease" ;
VAL_ 122 MCU_ActTrqValid 1 "valid" 0 "invalid" ;
VAL_ 122 MCU_ActualSpeedValid 1 "valid" 0 "invalid" ;
VAL_ 124 MCU_TempStatus 3 "Over Heating" 2 "Heating alarm 2" 1 "Heating alarm 1" 0 "Normal Temperature" ;
VAL_ 125 MCU_bDmpCActv 1 "Damping Off" 0 "Damping On" ;
VAL_ 125 MCU_stGateDrv 2 "PWMrun" 1 "FreeWheel" 0 "ASC" ;
VAL_ 125 MCU_VCUWorkMode 8 "Speed Control" 7 "Motor Active Hearting" 6 "Afterrun" 5 "ActiveDischarge" 4 "Shutdown" 3 "Torque Control" 2 "Ready" 1 "Standby" 0 "Initialization" ;
VAL_ 709 MCU_bDernOvrIdc 1 "Derating" 0 "Normal " ;
VAL_ 709 MCU_bDernOvrUdc 1 "Derating" 0 "Normal " ;
VAL_ 709 MCU_bDernStrTemp 1 "Derating" 0 "Normal " ;
VAL_ 709 MCU_bDernTrqMax 1 "Derating" 0 "Normal " ;
VAL_ 709 MCU_bDernTrqMin 1 "Derating" 0 "Normal " ;
VAL_ 709 MCU_bDernUndrIdc 1 "Derating" 0 "Normal " ;
VAL_ 709 MCU_bDernUndrUdc 1 "Derating" 0 "Normal " ;
VAL_ 709 MCU_bReadyHv 1 "Precharge Finished" 0 "PreCharge Not Finished" ;
VAL_ 709 MCU_bDernTempIGBT 1 "Derating" 0 "Normal " ;
VAL_ 709 MCU_bDernTempCool 1 "Derating" 0 "Normal " ;
VAL_ 709 MCU_bDernN 1 "Derating" 0 "Normal " ;
VAL_ 709 MCU_stDischg 3 " Failed" 2 " Finished" 1 " Active" 0 " Standby" ;
VAL_ 710 MCU_FailCode1 4 " Fault Level4" 3 " Fault Level3" 2 " Fault Level2" 1 " Fault Level1" 0 "No Fault" ;
